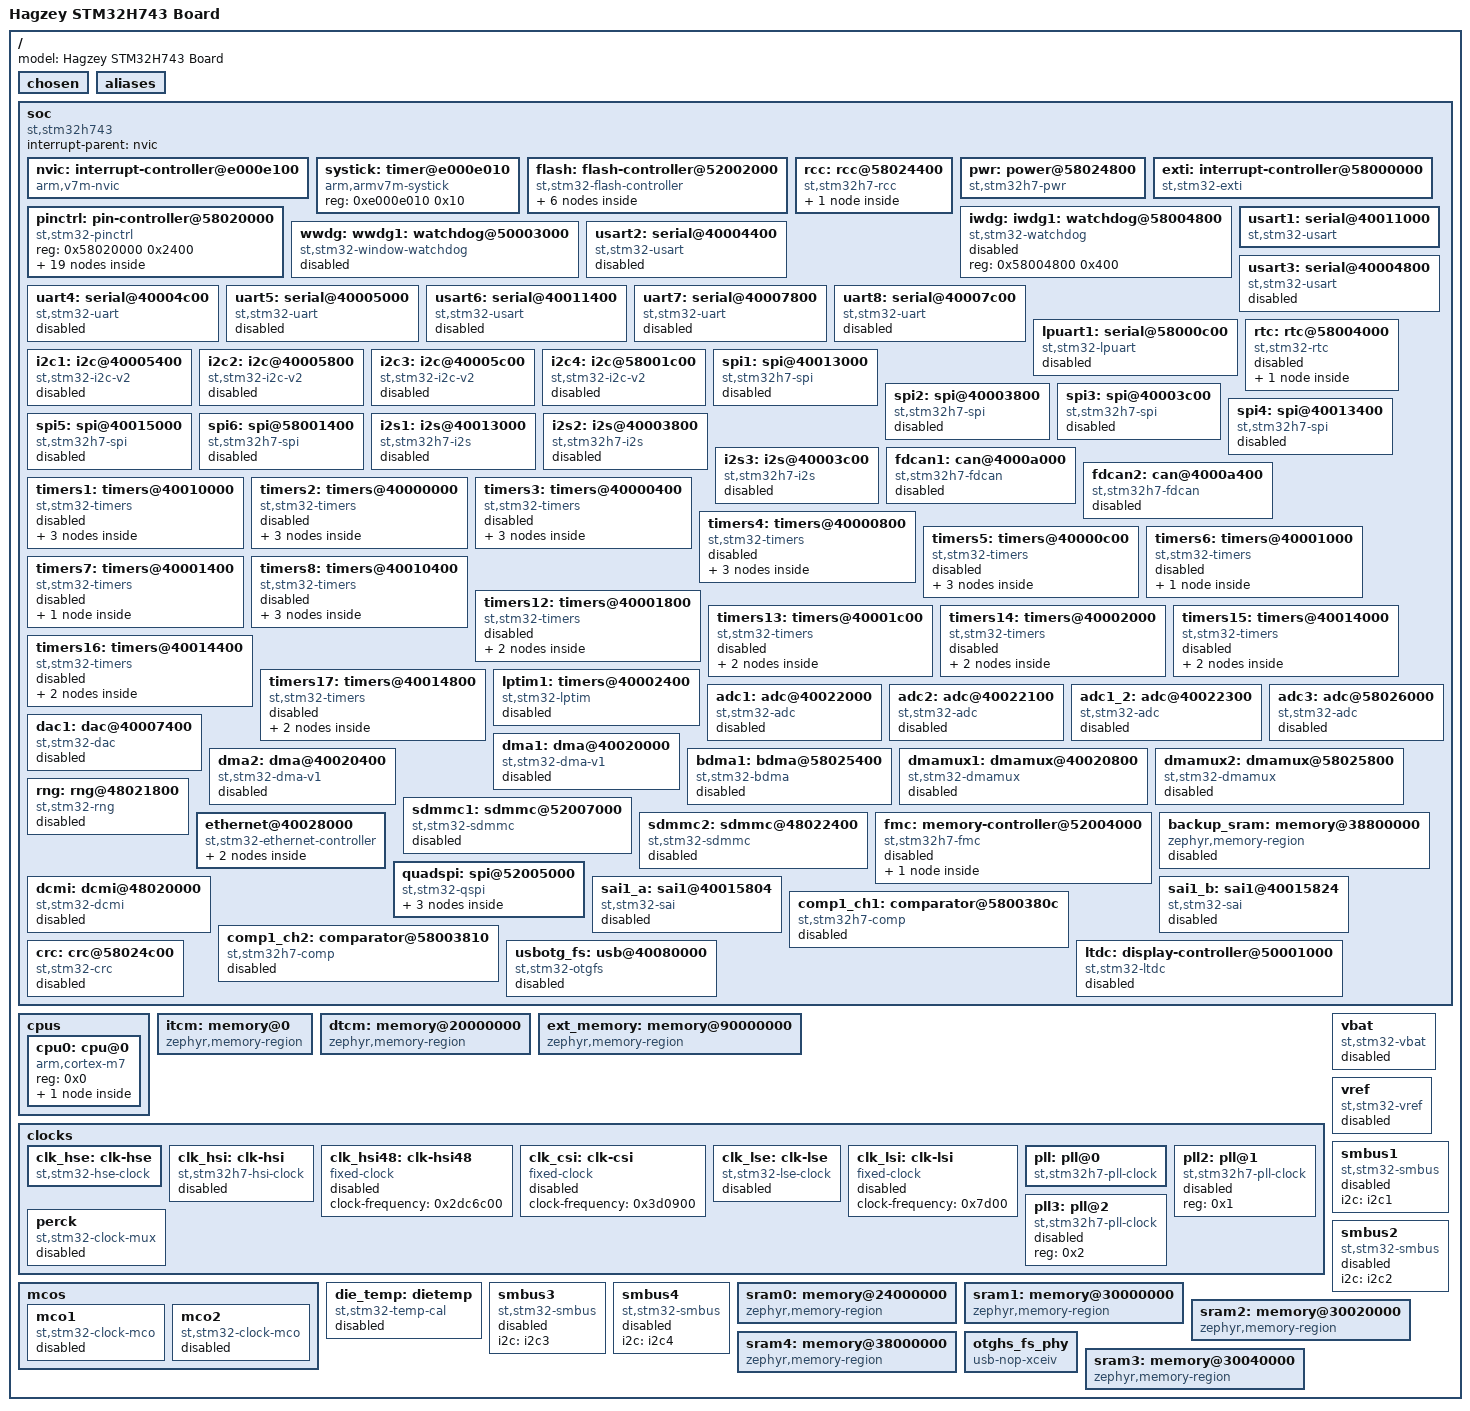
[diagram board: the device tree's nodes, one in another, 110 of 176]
/dts-v1/;

/* node '/' defined in zephyr/dts/common/skeleton.dtsi:9 */
/ {
	#address-cells = < 0x1 >;         /* in zephyr/dts/common/skeleton.dtsi:10 */
	#size-cells = < 0x1 >;            /* in zephyr/dts/common/skeleton.dtsi:11 */
	model = "Hagzey STM32H743 Board"; /* in ../Projects/stm32_system_on_module/fw/som/boards/hagzey/som/som.dts:8 */

	/* node '/chosen' defined in zephyr/dts/common/skeleton.dtsi:13 */
	chosen {
		zephyr,crc = &crc;                /* in zephyr/dts/arm/st/h7/stm32h7.dtsi:29 */
		zephyr,entropy = &rng;            /* in zephyr/dts/arm/st/h7/stm32h7.dtsi:30 */
		zephyr,flash-controller = &flash; /* in zephyr/dts/arm/st/h7/stm32h7.dtsi:31 */
		zephyr,sram = &sram0;             /* in ../Projects/stm32_system_on_module/fw/som/boards/hagzey/som/som.dts:11 */
		zephyr,flash = &flash0;           /* in ../Projects/stm32_system_on_module/fw/som/boards/hagzey/som/som.dts:12 */
		zephyr,console = &usart1;         /* in ../Projects/stm32_system_on_module/fw/som/boards/hagzey/som/som.dts:13 */
		zephyr,shell-uart = &usart1;      /* in ../Projects/stm32_system_on_module/fw/som/boards/hagzey/som/som.dts:14 */
	};

	/* node '/aliases' defined in zephyr/dts/common/skeleton.dtsi:15 */
	aliases {
	};

	/* node '/soc' defined in zephyr/dts/arm/armv7-m.dtsi:6 */
	soc {
		#address-cells = < 0x1 >;     /* in zephyr/dts/arm/armv7-m.dtsi:7 */
		#size-cells = < 0x1 >;        /* in zephyr/dts/arm/armv7-m.dtsi:8 */
		interrupt-parent = < &nvic >; /* in zephyr/dts/arm/armv7-m.dtsi:10 */
		ranges;                       /* in zephyr/dts/arm/armv7-m.dtsi:11 */
		compatible = "st,stm32h743",
		             "st,stm32h7",
		             "simple-bus";    /* in zephyr/dts/arm/st/h7/stm32h743.dtsi:12 */

		/* node '/soc/interrupt-controller@e000e100' defined in zephyr/dts/arm/armv7-m.dtsi:13 */
		nvic: interrupt-controller@e000e100 {
			#address-cells = < 0x1 >;            /* in zephyr/dts/arm/armv7-m.dtsi:14 */
			compatible = "arm,v7m-nvic";         /* in zephyr/dts/arm/armv7-m.dtsi:15 */
			reg = < 0xe000e100 0xc00 >;          /* in zephyr/dts/arm/armv7-m.dtsi:16 */
			interrupt-controller;                /* in zephyr/dts/arm/armv7-m.dtsi:17 */
			#interrupt-cells = < 0x2 >;          /* in zephyr/dts/arm/armv7-m.dtsi:18 */
			arm,num-irq-priority-bits = < 0x4 >; /* in zephyr/dts/arm/st/h7/stm32h7.dtsi:1355 */
			phandle = < 0x1 >;                   /* in zephyr/dts/arm/armv7-m.dtsi:10 */
		};

		/* node '/soc/timer@e000e010' defined in zephyr/dts/arm/armv7-m.dtsi:21 */
		systick: timer@e000e010 {
			compatible = "arm,armv7m-systick"; /* in zephyr/dts/arm/armv7-m.dtsi:22 */
			reg = < 0xe000e010 0x10 >;         /* in zephyr/dts/arm/armv7-m.dtsi:23 */
		};

		/* node '/soc/flash-controller@52002000' defined in zephyr/dts/arm/st/h7/stm32h7.dtsi:162 */
		flash: flash-controller@52002000 {
			compatible = "st,stm32-flash-controller",
			             "st,stm32h7-flash-controller"; /* in zephyr/dts/arm/st/h7/stm32h7.dtsi:163 */
			reg = < 0x52002000 0x400 >;                 /* in zephyr/dts/arm/st/h7/stm32h7.dtsi:164 */
			interrupts = < 0x4 0x0 >;                   /* in zephyr/dts/arm/st/h7/stm32h7.dtsi:165 */
			#address-cells = < 0x1 >;                   /* in zephyr/dts/arm/st/h7/stm32h7.dtsi:167 */
			#size-cells = < 0x1 >;                      /* in zephyr/dts/arm/st/h7/stm32h7.dtsi:168 */

			/* node '/soc/flash-controller@52002000/flash@1ff1e000' defined in zephyr/dts/arm/st/h7/stm32h7.dtsi:174 */
			flash@1ff1e000 {
				compatible = "st,stm32-nvm-otp"; /* in zephyr/dts/arm/st/h7/stm32h7.dtsi:175 */
				reg = < 0x1ff1e000 0x2000 >;     /* in zephyr/dts/arm/st/h7/stm32h7.dtsi:176 */

				/* node '/soc/flash-controller@52002000/flash@1ff1e000/nvmem-layout' defined in zephyr/dts/arm/st/h7/stm32h7.dtsi:178 */
				nvmem-layout {
					compatible = "fixed-layout"; /* in zephyr/dts/arm/st/h7/stm32h7.dtsi:179 */
					#address-cells = < 0x1 >;    /* in zephyr/dts/arm/st/h7/stm32h7.dtsi:180 */
					#size-cells = < 0x1 >;       /* in zephyr/dts/arm/st/h7/stm32h7.dtsi:181 */

					/* node '/soc/flash-controller@52002000/flash@1ff1e000/nvmem-layout/ts-cal1@820' defined in zephyr/dts/arm/st/h7/stm32h7.dtsi:183 */
					ts_cal1_otp: ts-cal1@820 {
						reg = < 0x820 0x2 >;         /* in zephyr/dts/arm/st/h7/stm32h7.dtsi:184 */
						#nvmem-cell-cells = < 0x0 >; /* in zephyr/dts/arm/st/h7/stm32h7.dtsi:185 */
						read-only;                   /* in zephyr/dts/arm/st/h7/stm32h7.dtsi:186 */
						phandle = < 0x12 >;          /* in zephyr/dts/arm/st/h7/stm32h7.dtsi:1297 */
					};

					/* node '/soc/flash-controller@52002000/flash@1ff1e000/nvmem-layout/ts-cal2@840' defined in zephyr/dts/arm/st/h7/stm32h7.dtsi:189 */
					ts_cal2_otp: ts-cal2@840 {
						reg = < 0x840 0x2 >;         /* in zephyr/dts/arm/st/h7/stm32h7.dtsi:190 */
						#nvmem-cell-cells = < 0x0 >; /* in zephyr/dts/arm/st/h7/stm32h7.dtsi:191 */
						read-only;                   /* in zephyr/dts/arm/st/h7/stm32h7.dtsi:192 */
						phandle = < 0x13 >;          /* in zephyr/dts/arm/st/h7/stm32h7.dtsi:1297 */
					};

					/* node '/soc/flash-controller@52002000/flash@1ff1e000/nvmem-layout/vrefint@860' defined in zephyr/dts/arm/st/h7/stm32h7.dtsi:195 */
					vrefint_otp: vrefint@860 {
						reg = < 0x860 0x2 >;         /* in zephyr/dts/arm/st/h7/stm32h7.dtsi:196 */
						#nvmem-cell-cells = < 0x0 >; /* in zephyr/dts/arm/st/h7/stm32h7.dtsi:197 */
						read-only;                   /* in zephyr/dts/arm/st/h7/stm32h7.dtsi:198 */
						phandle = < 0x15 >;          /* in zephyr/dts/arm/st/h7/stm32h7.dtsi:1315 */
					};
				};
			};

			/* node '/soc/flash-controller@52002000/flash@8000000' defined in zephyr/dts/arm/st/h7/stm32h742.dtsi:15 */
			flash0: flash@8000000 {
				compatible = "st,stm32-nv-flash",
				             "soc-nv-flash";      /* in zephyr/dts/arm/st/h7/stm32h742.dtsi:16 */
				write-block-size = < 0x20 >;      /* in zephyr/dts/arm/st/h7/stm32h742.dtsi:17 */
				erase-block-size = < 0x20000 >;   /* in zephyr/dts/arm/st/h7/stm32h742.dtsi:18 */
				max-erase-time = < 0xfa0 >;       /* in zephyr/dts/arm/st/h7/stm32h742.dtsi:20 */
				reg = < 0x8000000 0x200000 >;     /* in zephyr/dts/arm/st/h7/stm32h743Xi.dtsi:13 */
			};
		};

		/* node '/soc/rcc@58024400' defined in zephyr/dts/arm/st/h7/stm32h7.dtsi:204 */
		rcc: rcc@58024400 {
			compatible = "st,stm32h7-rcc";    /* in zephyr/dts/arm/st/h7/stm32h7.dtsi:205 */
			#clock-cells = < 0x2 >;           /* in zephyr/dts/arm/st/h7/stm32h7.dtsi:206 */
			reg = < 0x58024400 0x400 >;       /* in zephyr/dts/arm/st/h7/stm32h7.dtsi:207 */
			clocks = < &pll >;                /* in ../Projects/stm32_system_on_module/fw/som/boards/hagzey/som/som.dts:77 */
			clock-frequency = < 0x1c9c3800 >; /* in ../Projects/stm32_system_on_module/fw/som/boards/hagzey/som/som.dts:78 */
			d1cpre = < 0x1 >;                 /* in ../Projects/stm32_system_on_module/fw/som/boards/hagzey/som/som.dts:79 */
			hpre = < 0x2 >;                   /* in ../Projects/stm32_system_on_module/fw/som/boards/hagzey/som/som.dts:80 */
			d1ppre = < 0x2 >;                 /* in ../Projects/stm32_system_on_module/fw/som/boards/hagzey/som/som.dts:81 */
			d2ppre1 = < 0x2 >;                /* in ../Projects/stm32_system_on_module/fw/som/boards/hagzey/som/som.dts:82 */
			d2ppre2 = < 0x2 >;                /* in ../Projects/stm32_system_on_module/fw/som/boards/hagzey/som/som.dts:83 */
			d3ppre = < 0x2 >;                 /* in ../Projects/stm32_system_on_module/fw/som/boards/hagzey/som/som.dts:84 */
			phandle = < 0x3 >;                /* in zephyr/dts/arm/st/h7/stm32h7.dtsi:230 */

			/* node '/soc/rcc@58024400/reset-controller' defined in zephyr/dts/arm/st/h7/stm32h7.dtsi:209 */
			rctl: reset-controller {
				compatible = "st,stm32-rcc-rctl"; /* in zephyr/dts/arm/st/h7/stm32h7.dtsi:210 */
				#reset-cells = < 0x1 >;           /* in zephyr/dts/arm/st/h7/stm32h7.dtsi:211 */
				phandle = < 0x4 >;                /* in zephyr/dts/arm/st/h7/stm32h7.dtsi:353 */
			};
		};

		/* node '/soc/power@58024800' defined in zephyr/dts/arm/st/h7/stm32h7.dtsi:215 */
		pwr: power@58024800 {
			compatible = "st,stm32h7-pwr"; /* in zephyr/dts/arm/st/h7/stm32h7.dtsi:220 */
			reg = < 0x58024800 0x400 >;    /* in zephyr/dts/arm/st/h7/stm32h7.dtsi:221 */
			power-supply = "ldo";          /* in ../Projects/stm32_system_on_module/fw/som/boards/hagzey/som/som.dts:89 */
		};

		/* node '/soc/interrupt-controller@58000000' defined in zephyr/dts/arm/st/h7/stm32h7.dtsi:224 */
		exti: interrupt-controller@58000000 {
			compatible = "st,stm32-exti";  /* in zephyr/dts/arm/st/h7/stm32h7.dtsi:225 */
			interrupt-controller;          /* in zephyr/dts/arm/st/h7/stm32h7.dtsi:226 */
			#interrupt-cells = < 0x1 >;    /* in zephyr/dts/arm/st/h7/stm32h7.dtsi:227 */
			#address-cells = < 0x0 >;      /* in zephyr/dts/arm/st/h7/stm32h7.dtsi:228 */
			reg = < 0x58000000 0x400 >;    /* in zephyr/dts/arm/st/h7/stm32h7.dtsi:229 */
			clocks = < &rcc 0xf4 0x2 >;    /* in zephyr/dts/arm/st/h7/stm32h7.dtsi:230 */
			num-lines = < 0x60 >;          /* in zephyr/dts/arm/st/h7/stm32h7.dtsi:231 */
			interrupts = < 0x6 0x0 >,
			             < 0x7 0x0 >,
			             < 0x8 0x0 >,
			             < 0x9 0x0 >,
			             < 0xa 0x0 >,
			             < 0x17 0x0 >,
			             < 0x28 0x0 >;     /* in zephyr/dts/arm/st/h7/stm32h7.dtsi:232 */
			interrupt-names = "line0",
			                  "line1",
			                  "line2",
			                  "line3",
			                  "line4",
			                  "line5-9",
			                  "line10-15"; /* in zephyr/dts/arm/st/h7/stm32h7.dtsi:234 */
			line-ranges = < 0x0 0x1 >,
			              < 0x1 0x1 >,
			              < 0x2 0x1 >,
			              < 0x3 0x1 >,
			              < 0x4 0x1 >,
			              < 0x5 0x5 >,
			              < 0xa 0x6 >;     /* in zephyr/dts/arm/st/h7/stm32h7.dtsi:236 */
		};

		/* node '/soc/pin-controller@58020000' defined in zephyr/dts/arm/st/h7/stm32h7.dtsi:240 */
		pinctrl: pin-controller@58020000 {
			compatible = "st,stm32-pinctrl"; /* in zephyr/dts/arm/st/h7/stm32h7.dtsi:241 */
			#address-cells = < 0x1 >;        /* in zephyr/dts/arm/st/h7/stm32h7.dtsi:242 */
			#size-cells = < 0x1 >;           /* in zephyr/dts/arm/st/h7/stm32h7.dtsi:243 */
			reg = < 0x58020000 0x2400 >;     /* in zephyr/dts/arm/st/h7/stm32h7.dtsi:244 */

			/* node '/soc/pin-controller@58020000/gpio@58020000' defined in zephyr/dts/arm/st/h7/stm32h7.dtsi:246 */
			gpioa: gpio@58020000 {
				compatible = "st,stm32-gpio"; /* in zephyr/dts/arm/st/h7/stm32h7.dtsi:247 */
				gpio-controller;              /* in zephyr/dts/arm/st/h7/stm32h7.dtsi:248 */
				#gpio-cells = < 0x2 >;        /* in zephyr/dts/arm/st/h7/stm32h7.dtsi:249 */
				reg = < 0x58020000 0x400 >;   /* in zephyr/dts/arm/st/h7/stm32h7.dtsi:250 */
				clocks = < &rcc 0xe0 0x1 >;   /* in zephyr/dts/arm/st/h7/stm32h7.dtsi:251 */
			};

			/* node '/soc/pin-controller@58020000/gpio@58020400' defined in zephyr/dts/arm/st/h7/stm32h7.dtsi:254 */
			gpiob: gpio@58020400 {
				compatible = "st,stm32-gpio"; /* in zephyr/dts/arm/st/h7/stm32h7.dtsi:255 */
				gpio-controller;              /* in zephyr/dts/arm/st/h7/stm32h7.dtsi:256 */
				#gpio-cells = < 0x2 >;        /* in zephyr/dts/arm/st/h7/stm32h7.dtsi:257 */
				reg = < 0x58020400 0x400 >;   /* in zephyr/dts/arm/st/h7/stm32h7.dtsi:258 */
				clocks = < &rcc 0xe0 0x2 >;   /* in zephyr/dts/arm/st/h7/stm32h7.dtsi:259 */
			};

			/* node '/soc/pin-controller@58020000/gpio@58020800' defined in zephyr/dts/arm/st/h7/stm32h7.dtsi:262 */
			gpioc: gpio@58020800 {
				compatible = "st,stm32-gpio"; /* in zephyr/dts/arm/st/h7/stm32h7.dtsi:263 */
				gpio-controller;              /* in zephyr/dts/arm/st/h7/stm32h7.dtsi:264 */
				#gpio-cells = < 0x2 >;        /* in zephyr/dts/arm/st/h7/stm32h7.dtsi:265 */
				reg = < 0x58020800 0x400 >;   /* in zephyr/dts/arm/st/h7/stm32h7.dtsi:266 */
				clocks = < &rcc 0xe0 0x4 >;   /* in zephyr/dts/arm/st/h7/stm32h7.dtsi:267 */
			};

			/* node '/soc/pin-controller@58020000/gpio@58020c00' defined in zephyr/dts/arm/st/h7/stm32h7.dtsi:270 */
			gpiod: gpio@58020c00 {
				compatible = "st,stm32-gpio"; /* in zephyr/dts/arm/st/h7/stm32h7.dtsi:271 */
				gpio-controller;              /* in zephyr/dts/arm/st/h7/stm32h7.dtsi:272 */
				#gpio-cells = < 0x2 >;        /* in zephyr/dts/arm/st/h7/stm32h7.dtsi:273 */
				reg = < 0x58020c00 0x400 >;   /* in zephyr/dts/arm/st/h7/stm32h7.dtsi:274 */
				clocks = < &rcc 0xe0 0x8 >;   /* in zephyr/dts/arm/st/h7/stm32h7.dtsi:275 */
			};

			/* node '/soc/pin-controller@58020000/gpio@58021000' defined in zephyr/dts/arm/st/h7/stm32h7.dtsi:278 */
			gpioe: gpio@58021000 {
				compatible = "st,stm32-gpio"; /* in zephyr/dts/arm/st/h7/stm32h7.dtsi:279 */
				gpio-controller;              /* in zephyr/dts/arm/st/h7/stm32h7.dtsi:280 */
				#gpio-cells = < 0x2 >;        /* in zephyr/dts/arm/st/h7/stm32h7.dtsi:281 */
				reg = < 0x58021000 0x400 >;   /* in zephyr/dts/arm/st/h7/stm32h7.dtsi:282 */
				clocks = < &rcc 0xe0 0x10 >;  /* in zephyr/dts/arm/st/h7/stm32h7.dtsi:283 */
			};

			/* node '/soc/pin-controller@58020000/gpio@58021400' defined in zephyr/dts/arm/st/h7/stm32h7.dtsi:286 */
			gpiof: gpio@58021400 {
				compatible = "st,stm32-gpio"; /* in zephyr/dts/arm/st/h7/stm32h7.dtsi:287 */
				gpio-controller;              /* in zephyr/dts/arm/st/h7/stm32h7.dtsi:288 */
				#gpio-cells = < 0x2 >;        /* in zephyr/dts/arm/st/h7/stm32h7.dtsi:289 */
				reg = < 0x58021400 0x400 >;   /* in zephyr/dts/arm/st/h7/stm32h7.dtsi:290 */
				clocks = < &rcc 0xe0 0x20 >;  /* in zephyr/dts/arm/st/h7/stm32h7.dtsi:291 */
			};

			/* node '/soc/pin-controller@58020000/gpio@58021800' defined in zephyr/dts/arm/st/h7/stm32h7.dtsi:294 */
			gpiog: gpio@58021800 {
				compatible = "st,stm32-gpio"; /* in zephyr/dts/arm/st/h7/stm32h7.dtsi:295 */
				gpio-controller;              /* in zephyr/dts/arm/st/h7/stm32h7.dtsi:296 */
				#gpio-cells = < 0x2 >;        /* in zephyr/dts/arm/st/h7/stm32h7.dtsi:297 */
				reg = < 0x58021800 0x400 >;   /* in zephyr/dts/arm/st/h7/stm32h7.dtsi:298 */
				clocks = < &rcc 0xe0 0x40 >;  /* in zephyr/dts/arm/st/h7/stm32h7.dtsi:299 */
			};

			/* node '/soc/pin-controller@58020000/gpio@58021c00' defined in zephyr/dts/arm/st/h7/stm32h7.dtsi:302 */
			gpioh: gpio@58021c00 {
				compatible = "st,stm32-gpio"; /* in zephyr/dts/arm/st/h7/stm32h7.dtsi:303 */
				gpio-controller;              /* in zephyr/dts/arm/st/h7/stm32h7.dtsi:304 */
				#gpio-cells = < 0x2 >;        /* in zephyr/dts/arm/st/h7/stm32h7.dtsi:305 */
				reg = < 0x58021c00 0x400 >;   /* in zephyr/dts/arm/st/h7/stm32h7.dtsi:306 */
				clocks = < &rcc 0xe0 0x80 >;  /* in zephyr/dts/arm/st/h7/stm32h7.dtsi:307 */
			};

			/* node '/soc/pin-controller@58020000/gpio@58022000' defined in zephyr/dts/arm/st/h7/stm32h7.dtsi:310 */
			gpioi: gpio@58022000 {
				compatible = "st,stm32-gpio"; /* in zephyr/dts/arm/st/h7/stm32h7.dtsi:311 */
				gpio-controller;              /* in zephyr/dts/arm/st/h7/stm32h7.dtsi:312 */
				#gpio-cells = < 0x2 >;        /* in zephyr/dts/arm/st/h7/stm32h7.dtsi:313 */
				reg = < 0x58022000 0x400 >;   /* in zephyr/dts/arm/st/h7/stm32h7.dtsi:314 */
				clocks = < &rcc 0xe0 0x100 >; /* in zephyr/dts/arm/st/h7/stm32h7.dtsi:315 */
			};

			/* node '/soc/pin-controller@58020000/gpio@58022400' defined in zephyr/dts/arm/st/h7/stm32h7.dtsi:318 */
			gpioj: gpio@58022400 {
				compatible = "st,stm32-gpio"; /* in zephyr/dts/arm/st/h7/stm32h7.dtsi:319 */
				gpio-controller;              /* in zephyr/dts/arm/st/h7/stm32h7.dtsi:320 */
				#gpio-cells = < 0x2 >;        /* in zephyr/dts/arm/st/h7/stm32h7.dtsi:321 */
				reg = < 0x58022400 0x400 >;   /* in zephyr/dts/arm/st/h7/stm32h7.dtsi:322 */
				clocks = < &rcc 0xe0 0x200 >; /* in zephyr/dts/arm/st/h7/stm32h7.dtsi:323 */
			};

			/* node '/soc/pin-controller@58020000/gpio@58022800' defined in zephyr/dts/arm/st/h7/stm32h7.dtsi:326 */
			gpiok: gpio@58022800 {
				compatible = "st,stm32-gpio"; /* in zephyr/dts/arm/st/h7/stm32h7.dtsi:327 */
				gpio-controller;              /* in zephyr/dts/arm/st/h7/stm32h7.dtsi:328 */
				#gpio-cells = < 0x2 >;        /* in zephyr/dts/arm/st/h7/stm32h7.dtsi:329 */
				reg = < 0x58022800 0x400 >;   /* in zephyr/dts/arm/st/h7/stm32h7.dtsi:330 */
				clocks = < &rcc 0xe0 0x400 >; /* in zephyr/dts/arm/st/h7/stm32h7.dtsi:331 */
			};

			/* node '/soc/pin-controller@58020000/quadspi_bk1_ncs_pb10' defined in modules/hal/stm32/dts/st/h7/stm32h743vitx-pinctrl.dtsi:1854 */
			quadspi_bk1_ncs_pb10: quadspi_bk1_ncs_pb10 {
				pinmux = < 0x349 >;            /* in ../Projects/stm32_system_on_module/fw/som/boards/hagzey/som/som.dts:26 */
				slew-rate = "very-high-speed"; /* in ../Projects/stm32_system_on_module/fw/som/boards/hagzey/som/som.dts:27 */
				phandle = < 0xa >;             /* in ../Projects/stm32_system_on_module/fw/som/boards/hagzey/som/som.dts:95 */
			};

			/* node '/soc/pin-controller@58020000/quadspi_bk1_io2_pe2' defined in modules/hal/stm32/dts/st/h7/stm32h743vitx-pinctrl.dtsi:1889 */
			quadspi_bk1_io2_pe2: quadspi_bk1_io2_pe2 {
				pinmux = < 0x849 >;            /* in ../Projects/stm32_system_on_module/fw/som/boards/hagzey/som/som.dts:41 */
				slew-rate = "very-high-speed"; /* in ../Projects/stm32_system_on_module/fw/som/boards/hagzey/som/som.dts:42 */
				phandle = < 0xd >;             /* in ../Projects/stm32_system_on_module/fw/som/boards/hagzey/som/som.dts:95 */
			};

			/* node '/soc/pin-controller@58020000/usart1_rx_pb15' defined in modules/hal/stm32/dts/st/h7/stm32h743vitx-pinctrl.dtsi:3125 */
			usart1_rx_pb15: usart1_rx_pb15 {
				pinmux = < 0x3e4 >; /* in modules/hal/stm32/dts/st/h7/stm32h743vitx-pinctrl.dtsi:3126 */
				phandle = < 0x6 >;  /* in ../Projects/stm32_system_on_module/fw/som/boards/hagzey/som/som.dts:53 */
			};

			/* node '/soc/pin-controller@58020000/usart1_tx_pb14' defined in modules/hal/stm32/dts/st/h7/stm32h743vitx-pinctrl.dtsi:3223 */
			usart1_tx_pb14: usart1_tx_pb14 {
				pinmux = < 0x3c4 >; /* in modules/hal/stm32/dts/st/h7/stm32h743vitx-pinctrl.dtsi:3224 */
				bias-pull-up;       /* in modules/hal/stm32/dts/st/h7/stm32h743vitx-pinctrl.dtsi:3225 */
				phandle = < 0x5 >;  /* in ../Projects/stm32_system_on_module/fw/som/boards/hagzey/som/som.dts:53 */
			};

			/* node '/soc/pin-controller@58020000/quadspi_clk_pf10' defined in ../Projects/stm32_system_on_module/fw/som/boards/hagzey/som/som.dts:20 */
			quadspi_clk_pf10: quadspi_clk_pf10 {
				pinmux = < 0xb49 >;            /* in ../Projects/stm32_system_on_module/fw/som/boards/hagzey/som/som.dts:21 */
				slew-rate = "very-high-speed"; /* in ../Projects/stm32_system_on_module/fw/som/boards/hagzey/som/som.dts:22 */
				phandle = < 0x9 >;             /* in ../Projects/stm32_system_on_module/fw/som/boards/hagzey/som/som.dts:95 */
			};

			/* node '/soc/pin-controller@58020000/quadspi_bk1_io0_pf8' defined in ../Projects/stm32_system_on_module/fw/som/boards/hagzey/som/som.dts:30 */
			quadspi_bk1_io0_pf8: quadspi_bk1_io0_pf8 {
				pinmux = < 0xb0a >;            /* in ../Projects/stm32_system_on_module/fw/som/boards/hagzey/som/som.dts:31 */
				slew-rate = "very-high-speed"; /* in ../Projects/stm32_system_on_module/fw/som/boards/hagzey/som/som.dts:32 */
				phandle = < 0xb >;             /* in ../Projects/stm32_system_on_module/fw/som/boards/hagzey/som/som.dts:95 */
			};

			/* node '/soc/pin-controller@58020000/quadspi_bk1_io1_pf9' defined in ../Projects/stm32_system_on_module/fw/som/boards/hagzey/som/som.dts:35 */
			quadspi_bk1_io1_pf9: quadspi_bk1_io1_pf9 {
				pinmux = < 0xb2a >;            /* in ../Projects/stm32_system_on_module/fw/som/boards/hagzey/som/som.dts:36 */
				slew-rate = "very-high-speed"; /* in ../Projects/stm32_system_on_module/fw/som/boards/hagzey/som/som.dts:37 */
				phandle = < 0xc >;             /* in ../Projects/stm32_system_on_module/fw/som/boards/hagzey/som/som.dts:95 */
			};

			/* node '/soc/pin-controller@58020000/quadspi_bk1_io3_pf6' defined in ../Projects/stm32_system_on_module/fw/som/boards/hagzey/som/som.dts:45 */
			quadspi_bk1_io3_pf6: quadspi_bk1_io3_pf6 {
				pinmux = < 0xac9 >;            /* in ../Projects/stm32_system_on_module/fw/som/boards/hagzey/som/som.dts:46 */
				slew-rate = "very-high-speed"; /* in ../Projects/stm32_system_on_module/fw/som/boards/hagzey/som/som.dts:47 */
				phandle = < 0xe >;             /* in ../Projects/stm32_system_on_module/fw/som/boards/hagzey/som/som.dts:95 */
			};
		};

		/* node '/soc/watchdog@58004800' defined in zephyr/dts/arm/st/h7/stm32h7.dtsi:335 */
		iwdg: iwdg1: watchdog@58004800 {
			compatible = "st,stm32-watchdog"; /* in zephyr/dts/arm/st/h7/stm32h7.dtsi:336 */
			reg = < 0x58004800 0x400 >;       /* in zephyr/dts/arm/st/h7/stm32h7.dtsi:337 */
			status = "disabled";              /* in zephyr/dts/arm/st/h7/stm32h7.dtsi:338 */
		};

		/* node '/soc/watchdog@50003000' defined in zephyr/dts/arm/st/h7/stm32h7.dtsi:341 */
		wwdg: wwdg1: watchdog@50003000 {
			compatible = "st,stm32-window-watchdog"; /* in zephyr/dts/arm/st/h7/stm32h7.dtsi:342 */
			reg = < 0x50003000 0x1000 >;             /* in zephyr/dts/arm/st/h7/stm32h7.dtsi:343 */
			clocks = < &rcc 0xe4 0x40 >;             /* in zephyr/dts/arm/st/h7/stm32h7.dtsi:344 */
			interrupts = < 0x0 0x7 >;                /* in zephyr/dts/arm/st/h7/stm32h7.dtsi:345 */
			status = "disabled";                     /* in zephyr/dts/arm/st/h7/stm32h7.dtsi:346 */
		};

		/* node '/soc/serial@40011000' defined in zephyr/dts/arm/st/h7/stm32h7.dtsi:349 */
		usart1: serial@40011000 {
			compatible = "st,stm32-usart",
			             "st,stm32-uart";                    /* in zephyr/dts/arm/st/h7/stm32h7.dtsi:350 */
			reg = < 0x40011000 0x400 >;                      /* in zephyr/dts/arm/st/h7/stm32h7.dtsi:351 */
			clocks = < &rcc 0xf0 0x10 >;                     /* in zephyr/dts/arm/st/h7/stm32h7.dtsi:352 */
			resets = < &rctl 0x1304 >;                       /* in zephyr/dts/arm/st/h7/stm32h7.dtsi:353 */
			interrupts = < 0x25 0x0 >;                       /* in zephyr/dts/arm/st/h7/stm32h7.dtsi:354 */
			pinctrl-0 = < &usart1_tx_pb14 &usart1_rx_pb15 >; /* in ../Projects/stm32_system_on_module/fw/som/boards/hagzey/som/som.dts:53 */
			pinctrl-names = "default";                       /* in ../Projects/stm32_system_on_module/fw/som/boards/hagzey/som/som.dts:54 */
			current-speed = < 0xe100 >;                      /* in ../Projects/stm32_system_on_module/fw/som/boards/hagzey/som/som.dts:55 */
			status = "okay";                                 /* in ../Projects/stm32_system_on_module/fw/som/boards/hagzey/som/som.dts:56 */
		};

		/* node '/soc/serial@40004400' defined in zephyr/dts/arm/st/h7/stm32h7.dtsi:358 */
		usart2: serial@40004400 {
			compatible = "st,stm32-usart",
			             "st,stm32-uart";   /* in zephyr/dts/arm/st/h7/stm32h7.dtsi:359 */
			reg = < 0x40004400 0x400 >;     /* in zephyr/dts/arm/st/h7/stm32h7.dtsi:360 */
			clocks = < &rcc 0xe8 0x20000 >; /* in zephyr/dts/arm/st/h7/stm32h7.dtsi:361 */
			resets = < &rctl 0x1211 >;      /* in zephyr/dts/arm/st/h7/stm32h7.dtsi:362 */
			interrupts = < 0x26 0x0 >;      /* in zephyr/dts/arm/st/h7/stm32h7.dtsi:363 */
			status = "disabled";            /* in zephyr/dts/arm/st/h7/stm32h7.dtsi:364 */
		};

		/* node '/soc/serial@40004800' defined in zephyr/dts/arm/st/h7/stm32h7.dtsi:367 */
		usart3: serial@40004800 {
			compatible = "st,stm32-usart",
			             "st,stm32-uart";   /* in zephyr/dts/arm/st/h7/stm32h7.dtsi:368 */
			reg = < 0x40004800 0x400 >;     /* in zephyr/dts/arm/st/h7/stm32h7.dtsi:369 */
			clocks = < &rcc 0xe8 0x40000 >; /* in zephyr/dts/arm/st/h7/stm32h7.dtsi:370 */
			resets = < &rctl 0x1212 >;      /* in zephyr/dts/arm/st/h7/stm32h7.dtsi:371 */
			interrupts = < 0x27 0x0 >;      /* in zephyr/dts/arm/st/h7/stm32h7.dtsi:372 */
			status = "disabled";            /* in zephyr/dts/arm/st/h7/stm32h7.dtsi:373 */
		};

		/* node '/soc/serial@40004c00' defined in zephyr/dts/arm/st/h7/stm32h7.dtsi:376 */
		uart4: serial@40004c00 {
			compatible = "st,stm32-uart";   /* in zephyr/dts/arm/st/h7/stm32h7.dtsi:377 */
			reg = < 0x40004c00 0x400 >;     /* in zephyr/dts/arm/st/h7/stm32h7.dtsi:378 */
			clocks = < &rcc 0xe8 0x80000 >; /* in zephyr/dts/arm/st/h7/stm32h7.dtsi:379 */
			resets = < &rctl 0x1213 >;      /* in zephyr/dts/arm/st/h7/stm32h7.dtsi:380 */
			interrupts = < 0x34 0x0 >;      /* in zephyr/dts/arm/st/h7/stm32h7.dtsi:381 */
			status = "disabled";            /* in zephyr/dts/arm/st/h7/stm32h7.dtsi:382 */
		};

		/* node '/soc/serial@40005000' defined in zephyr/dts/arm/st/h7/stm32h7.dtsi:385 */
		uart5: serial@40005000 {
			compatible = "st,stm32-uart";    /* in zephyr/dts/arm/st/h7/stm32h7.dtsi:386 */
			reg = < 0x40005000 0x400 >;      /* in zephyr/dts/arm/st/h7/stm32h7.dtsi:387 */
			clocks = < &rcc 0xe8 0x100000 >; /* in zephyr/dts/arm/st/h7/stm32h7.dtsi:388 */
			resets = < &rctl 0x1214 >;       /* in zephyr/dts/arm/st/h7/stm32h7.dtsi:389 */
			interrupts = < 0x35 0x0 >;       /* in zephyr/dts/arm/st/h7/stm32h7.dtsi:390 */
			status = "disabled";             /* in zephyr/dts/arm/st/h7/stm32h7.dtsi:391 */
		};

		/* node '/soc/serial@40011400' defined in zephyr/dts/arm/st/h7/stm32h7.dtsi:394 */
		usart6: serial@40011400 {
			compatible = "st,stm32-usart",
			             "st,stm32-uart";  /* in zephyr/dts/arm/st/h7/stm32h7.dtsi:395 */
			reg = < 0x40011400 0x400 >;    /* in zephyr/dts/arm/st/h7/stm32h7.dtsi:396 */
			clocks = < &rcc 0xf0 0x20 >;   /* in zephyr/dts/arm/st/h7/stm32h7.dtsi:397 */
			resets = < &rctl 0x1305 >;     /* in zephyr/dts/arm/st/h7/stm32h7.dtsi:398 */
			interrupts = < 0x47 0x0 >;     /* in zephyr/dts/arm/st/h7/stm32h7.dtsi:399 */
			status = "disabled";           /* in zephyr/dts/arm/st/h7/stm32h7.dtsi:400 */
		};

		/* node '/soc/serial@40007800' defined in zephyr/dts/arm/st/h7/stm32h7.dtsi:403 */
		uart7: serial@40007800 {
			compatible = "st,stm32-uart";      /* in zephyr/dts/arm/st/h7/stm32h7.dtsi:404 */
			reg = < 0x40007800 0x400 >;        /* in zephyr/dts/arm/st/h7/stm32h7.dtsi:405 */
			clocks = < &rcc 0xe8 0x40000000 >; /* in zephyr/dts/arm/st/h7/stm32h7.dtsi:406 */
			resets = < &rctl 0x121e >;         /* in zephyr/dts/arm/st/h7/stm32h7.dtsi:407 */
			interrupts = < 0x52 0x0 >;         /* in zephyr/dts/arm/st/h7/stm32h7.dtsi:408 */
			status = "disabled";               /* in zephyr/dts/arm/st/h7/stm32h7.dtsi:409 */
		};

		/* node '/soc/serial@40007c00' defined in zephyr/dts/arm/st/h7/stm32h7.dtsi:412 */
		uart8: serial@40007c00 {
			compatible = "st,stm32-uart";      /* in zephyr/dts/arm/st/h7/stm32h7.dtsi:413 */
			reg = < 0x40007c00 0x400 >;        /* in zephyr/dts/arm/st/h7/stm32h7.dtsi:414 */
			clocks = < &rcc 0xe8 0x80000000 >; /* in zephyr/dts/arm/st/h7/stm32h7.dtsi:415 */
			resets = < &rctl 0x121f >;         /* in zephyr/dts/arm/st/h7/stm32h7.dtsi:416 */
			interrupts = < 0x53 0x0 >;         /* in zephyr/dts/arm/st/h7/stm32h7.dtsi:417 */
			status = "disabled";               /* in zephyr/dts/arm/st/h7/stm32h7.dtsi:418 */
		};

		/* node '/soc/serial@58000c00' defined in zephyr/dts/arm/st/h7/stm32h7.dtsi:421 */
		lpuart1: serial@58000c00 {
			compatible = "st,stm32-lpuart",
			             "st,stm32-uart";   /* in zephyr/dts/arm/st/h7/stm32h7.dtsi:422 */
			reg = < 0x58000c00 0x400 >;     /* in zephyr/dts/arm/st/h7/stm32h7.dtsi:423 */
			clocks = < &rcc 0xf4 0x8 >;     /* in zephyr/dts/arm/st/h7/stm32h7.dtsi:424 */
			resets = < &rctl 0x1383 >;      /* in zephyr/dts/arm/st/h7/stm32h7.dtsi:425 */
			interrupts = < 0x8e 0x0 >;      /* in zephyr/dts/arm/st/h7/stm32h7.dtsi:426 */
			status = "disabled";            /* in zephyr/dts/arm/st/h7/stm32h7.dtsi:427 */
		};

		/* node '/soc/rtc@58004000' defined in zephyr/dts/arm/st/h7/stm32h7.dtsi:430 */
		rtc: rtc@58004000 {
			compatible = "st,stm32-rtc";    /* in zephyr/dts/arm/st/h7/stm32h7.dtsi:431 */
			reg = < 0x58004000 0x400 >;     /* in zephyr/dts/arm/st/h7/stm32h7.dtsi:432 */
			interrupts = < 0x29 0x0 >;      /* in zephyr/dts/arm/st/h7/stm32h7.dtsi:433 */
			clocks = < &rcc 0xf4 0x10000 >; /* in zephyr/dts/arm/st/h7/stm32h7.dtsi:434 */
			prescaler = < 0x8000 >;         /* in zephyr/dts/arm/st/h7/stm32h7.dtsi:435 */
			alarms-count = < 0x2 >;         /* in zephyr/dts/arm/st/h7/stm32h7.dtsi:436 */
			alrm-exti-line = < 0x11 >;      /* in zephyr/dts/arm/st/h7/stm32h7.dtsi:437 */
			status = "disabled";            /* in zephyr/dts/arm/st/h7/stm32h7.dtsi:438 */

			/* node '/soc/rtc@58004000/backup_regs' defined in zephyr/dts/arm/st/h7/stm32h742.dtsi:57 */
			bbram: backup_regs {
				compatible = "st,stm32-bbram"; /* in zephyr/dts/arm/st/h7/stm32h742.dtsi:58 */
				st,backup-regs = < 0x20 >;     /* in zephyr/dts/arm/st/h7/stm32h742.dtsi:59 */
				status = "disabled";           /* in zephyr/dts/arm/st/h7/stm32h742.dtsi:60 */
			};
		};

		/* node '/soc/i2c@40005400' defined in zephyr/dts/arm/st/h7/stm32h7.dtsi:441 */
		i2c1: i2c@40005400 {
			compatible = "st,stm32-i2c-v2";  /* in zephyr/dts/arm/st/h7/stm32h7.dtsi:442 */
			clock-frequency = < 0x186a0 >;   /* in zephyr/dts/arm/st/h7/stm32h7.dtsi:443 */
			#address-cells = < 0x1 >;        /* in zephyr/dts/arm/st/h7/stm32h7.dtsi:444 */
			#size-cells = < 0x0 >;           /* in zephyr/dts/arm/st/h7/stm32h7.dtsi:445 */
			reg = < 0x40005400 0x400 >;      /* in zephyr/dts/arm/st/h7/stm32h7.dtsi:446 */
			clocks = < &rcc 0xe8 0x200000 >; /* in zephyr/dts/arm/st/h7/stm32h7.dtsi:447 */
			interrupts = < 0x1f 0x0 >,
			             < 0x20 0x0 >;       /* in zephyr/dts/arm/st/h7/stm32h7.dtsi:448 */
			interrupt-names = "event",
			                  "error";       /* in zephyr/dts/arm/st/h7/stm32h7.dtsi:449 */
			status = "disabled";             /* in zephyr/dts/arm/st/h7/stm32h7.dtsi:450 */
			phandle = < 0x16 >;              /* in zephyr/dts/arm/st/h7/stm32h7.dtsi:1325 */
		};

		/* node '/soc/i2c@40005800' defined in zephyr/dts/arm/st/h7/stm32h7.dtsi:453 */
		i2c2: i2c@40005800 {
			compatible = "st,stm32-i2c-v2";  /* in zephyr/dts/arm/st/h7/stm32h7.dtsi:454 */
			clock-frequency = < 0x186a0 >;   /* in zephyr/dts/arm/st/h7/stm32h7.dtsi:455 */
			#address-cells = < 0x1 >;        /* in zephyr/dts/arm/st/h7/stm32h7.dtsi:456 */
			#size-cells = < 0x0 >;           /* in zephyr/dts/arm/st/h7/stm32h7.dtsi:457 */
			reg = < 0x40005800 0x400 >;      /* in zephyr/dts/arm/st/h7/stm32h7.dtsi:458 */
			clocks = < &rcc 0xe8 0x400000 >; /* in zephyr/dts/arm/st/h7/stm32h7.dtsi:459 */
			interrupts = < 0x21 0x0 >,
			             < 0x22 0x0 >;       /* in zephyr/dts/arm/st/h7/stm32h7.dtsi:460 */
			interrupt-names = "event",
			                  "error";       /* in zephyr/dts/arm/st/h7/stm32h7.dtsi:461 */
			status = "disabled";             /* in zephyr/dts/arm/st/h7/stm32h7.dtsi:462 */
			phandle = < 0x17 >;              /* in zephyr/dts/arm/st/h7/stm32h7.dtsi:1333 */
		};

		/* node '/soc/i2c@40005c00' defined in zephyr/dts/arm/st/h7/stm32h7.dtsi:465 */
		i2c3: i2c@40005c00 {
			compatible = "st,stm32-i2c-v2";  /* in zephyr/dts/arm/st/h7/stm32h7.dtsi:466 */
			clock-frequency = < 0x186a0 >;   /* in zephyr/dts/arm/st/h7/stm32h7.dtsi:467 */
			#address-cells = < 0x1 >;        /* in zephyr/dts/arm/st/h7/stm32h7.dtsi:468 */
			#size-cells = < 0x0 >;           /* in zephyr/dts/arm/st/h7/stm32h7.dtsi:469 */
			reg = < 0x40005c00 0x400 >;      /* in zephyr/dts/arm/st/h7/stm32h7.dtsi:470 */
			clocks = < &rcc 0xe8 0x800000 >; /* in zephyr/dts/arm/st/h7/stm32h7.dtsi:471 */
			interrupts = < 0x48 0x0 >,
			             < 0x49 0x0 >;       /* in zephyr/dts/arm/st/h7/stm32h7.dtsi:472 */
			interrupt-names = "event",
			                  "error";       /* in zephyr/dts/arm/st/h7/stm32h7.dtsi:473 */
			status = "disabled";             /* in zephyr/dts/arm/st/h7/stm32h7.dtsi:474 */
			phandle = < 0x18 >;              /* in zephyr/dts/arm/st/h7/stm32h7.dtsi:1341 */
		};

		/* node '/soc/i2c@58001c00' defined in zephyr/dts/arm/st/h7/stm32h7.dtsi:477 */
		i2c4: i2c@58001c00 {
			compatible = "st,stm32-i2c-v2"; /* in zephyr/dts/arm/st/h7/stm32h7.dtsi:478 */
			clock-frequency = < 0x186a0 >;  /* in zephyr/dts/arm/st/h7/stm32h7.dtsi:479 */
			#address-cells = < 0x1 >;       /* in zephyr/dts/arm/st/h7/stm32h7.dtsi:480 */
			#size-cells = < 0x0 >;          /* in zephyr/dts/arm/st/h7/stm32h7.dtsi:481 */
			reg = < 0x58001c00 0x400 >;     /* in zephyr/dts/arm/st/h7/stm32h7.dtsi:482 */
			clocks = < &rcc 0xf4 0x80 >;    /* in zephyr/dts/arm/st/h7/stm32h7.dtsi:483 */
			interrupts = < 0x5f 0x0 >,
			             < 0x60 0x0 >;      /* in zephyr/dts/arm/st/h7/stm32h7.dtsi:484 */
			interrupt-names = "event",
			                  "error";      /* in zephyr/dts/arm/st/h7/stm32h7.dtsi:485 */
			status = "disabled";            /* in zephyr/dts/arm/st/h7/stm32h7.dtsi:486 */
			phandle = < 0x19 >;             /* in zephyr/dts/arm/st/h7/stm32h7.dtsi:1349 */
		};

		/* node '/soc/spi@40013000' defined in zephyr/dts/arm/st/h7/stm32h7.dtsi:489 */
		spi1: spi@40013000 {
			compatible = "st,stm32h7-spi",
			             "st,stm32-spi-fifo",
			             "st,stm32-spi";            /* in zephyr/dts/arm/st/h7/stm32h7.dtsi:490 */
			#address-cells = < 0x1 >;               /* in zephyr/dts/arm/st/h7/stm32h7.dtsi:491 */
			#size-cells = < 0x0 >;                  /* in zephyr/dts/arm/st/h7/stm32h7.dtsi:492 */
			reg = < 0x40013000 0x400 >;             /* in zephyr/dts/arm/st/h7/stm32h7.dtsi:493 */
			clocks = < &rcc 0xf0 0x1000 >,
			         < &rcc 0x9 0x4c0050 >;         /* in zephyr/dts/arm/st/h7/stm32h7.dtsi:494 */
			interrupts = < 0x23 0x0 >;              /* in zephyr/dts/arm/st/h7/stm32h7.dtsi:496 */
			st,spi-data-width = "full-4-to-32-bit"; /* in zephyr/dts/arm/st/h7/stm32h7.dtsi:497 */
			fifo-size = < 0x10 >;                   /* in zephyr/dts/arm/st/h7/stm32h7.dtsi:498 */
			fifo-max-transfer-size = < 0xffff >;    /* in zephyr/dts/arm/st/h7/stm32h7.dtsi:499 */
			status = "disabled";                    /* in zephyr/dts/arm/st/h7/stm32h7.dtsi:500 */
		};

		/* node '/soc/spi@40003800' defined in zephyr/dts/arm/st/h7/stm32h7.dtsi:503 */
		spi2: spi@40003800 {
			compatible = "st,stm32h7-spi",
			             "st,stm32-spi-fifo",
			             "st,stm32-spi";            /* in zephyr/dts/arm/st/h7/stm32h7.dtsi:504 */
			#address-cells = < 0x1 >;               /* in zephyr/dts/arm/st/h7/stm32h7.dtsi:505 */
			#size-cells = < 0x0 >;                  /* in zephyr/dts/arm/st/h7/stm32h7.dtsi:506 */
			reg = < 0x40003800 0x400 >;             /* in zephyr/dts/arm/st/h7/stm32h7.dtsi:507 */
			clocks = < &rcc 0xe8 0x4000 >,
			         < &rcc 0x9 0x4c0050 >;         /* in zephyr/dts/arm/st/h7/stm32h7.dtsi:508 */
			interrupts = < 0x24 0x0 >;              /* in zephyr/dts/arm/st/h7/stm32h7.dtsi:510 */
			st,spi-data-width = "full-4-to-32-bit"; /* in zephyr/dts/arm/st/h7/stm32h7.dtsi:511 */
			fifo-size = < 0x10 >;                   /* in zephyr/dts/arm/st/h7/stm32h7.dtsi:512 */
			fifo-max-transfer-size = < 0xffff >;    /* in zephyr/dts/arm/st/h7/stm32h7.dtsi:513 */
			status = "disabled";                    /* in zephyr/dts/arm/st/h7/stm32h7.dtsi:514 */
		};

		/* node '/soc/spi@40003c00' defined in zephyr/dts/arm/st/h7/stm32h7.dtsi:517 */
		spi3: spi@40003c00 {
			compatible = "st,stm32h7-spi",
			             "st,stm32-spi-fifo",
			             "st,stm32-spi";            /* in zephyr/dts/arm/st/h7/stm32h7.dtsi:518 */
			#address-cells = < 0x1 >;               /* in zephyr/dts/arm/st/h7/stm32h7.dtsi:519 */
			#size-cells = < 0x0 >;                  /* in zephyr/dts/arm/st/h7/stm32h7.dtsi:520 */
			reg = < 0x40003c00 0x400 >;             /* in zephyr/dts/arm/st/h7/stm32h7.dtsi:521 */
			clocks = < &rcc 0xe8 0x8000 >,
			         < &rcc 0x9 0x4c0050 >;         /* in zephyr/dts/arm/st/h7/stm32h7.dtsi:522 */
			interrupts = < 0x33 0x0 >;              /* in zephyr/dts/arm/st/h7/stm32h7.dtsi:524 */
			st,spi-data-width = "full-4-to-32-bit"; /* in zephyr/dts/arm/st/h7/stm32h7.dtsi:525 */
			fifo-size = < 0x10 >;                   /* in zephyr/dts/arm/st/h7/stm32h7.dtsi:526 */
			fifo-max-transfer-size = < 0xffff >;    /* in zephyr/dts/arm/st/h7/stm32h7.dtsi:527 */
			status = "disabled";                    /* in zephyr/dts/arm/st/h7/stm32h7.dtsi:528 */
		};

		/* node '/soc/spi@40013400' defined in zephyr/dts/arm/st/h7/stm32h7.dtsi:531 */
		spi4: spi@40013400 {
			compatible = "st,stm32h7-spi",
			             "st,stm32-spi-fifo",
			             "st,stm32-spi";            /* in zephyr/dts/arm/st/h7/stm32h7.dtsi:532 */
			#address-cells = < 0x1 >;               /* in zephyr/dts/arm/st/h7/stm32h7.dtsi:533 */
			#size-cells = < 0x0 >;                  /* in zephyr/dts/arm/st/h7/stm32h7.dtsi:534 */
			reg = < 0x40013400 0x400 >;             /* in zephyr/dts/arm/st/h7/stm32h7.dtsi:535 */
			clocks = < &rcc 0xf0 0x2000 >;          /* in zephyr/dts/arm/st/h7/stm32h7.dtsi:536 */
			interrupts = < 0x54 0x0 >;              /* in zephyr/dts/arm/st/h7/stm32h7.dtsi:537 */
			st,spi-data-width = "full-4-to-16-bit"; /* in zephyr/dts/arm/st/h7/stm32h7.dtsi:538 */
			status = "disabled";                    /* in zephyr/dts/arm/st/h7/stm32h7.dtsi:539 */
			fifo-size = < 0x8 >;                    /* in zephyr/dts/arm/st/h7/stm32h7.dtsi:540 */
			fifo-max-transfer-size = < 0xffff >;    /* in zephyr/dts/arm/st/h7/stm32h7.dtsi:541 */
		};

		/* node '/soc/spi@40015000' defined in zephyr/dts/arm/st/h7/stm32h7.dtsi:544 */
		spi5: spi@40015000 {
			compatible = "st,stm32h7-spi",
			             "st,stm32-spi-fifo",
			             "st,stm32-spi";            /* in zephyr/dts/arm/st/h7/stm32h7.dtsi:545 */
			#address-cells = < 0x1 >;               /* in zephyr/dts/arm/st/h7/stm32h7.dtsi:546 */
			#size-cells = < 0x0 >;                  /* in zephyr/dts/arm/st/h7/stm32h7.dtsi:547 */
			reg = < 0x40015000 0x400 >;             /* in zephyr/dts/arm/st/h7/stm32h7.dtsi:548 */
			clocks = < &rcc 0xf0 0x100000 >;        /* in zephyr/dts/arm/st/h7/stm32h7.dtsi:549 */
			interrupts = < 0x55 0x0 >;              /* in zephyr/dts/arm/st/h7/stm32h7.dtsi:550 */
			st,spi-data-width = "full-4-to-16-bit"; /* in zephyr/dts/arm/st/h7/stm32h7.dtsi:551 */
			fifo-size = < 0x8 >;                    /* in zephyr/dts/arm/st/h7/stm32h7.dtsi:552 */
			fifo-max-transfer-size = < 0xffff >;    /* in zephyr/dts/arm/st/h7/stm32h7.dtsi:553 */
			status = "disabled";                    /* in zephyr/dts/arm/st/h7/stm32h7.dtsi:554 */
		};

		/* node '/soc/spi@58001400' defined in zephyr/dts/arm/st/h7/stm32h7.dtsi:557 */
		spi6: spi@58001400 {
			compatible = "st,stm32h7-spi",
			             "st,stm32-spi-fifo",
			             "st,stm32-spi";            /* in zephyr/dts/arm/st/h7/stm32h7.dtsi:558 */
			#address-cells = < 0x1 >;               /* in zephyr/dts/arm/st/h7/stm32h7.dtsi:559 */
			#size-cells = < 0x0 >;                  /* in zephyr/dts/arm/st/h7/stm32h7.dtsi:560 */
			reg = < 0x58001400 0x400 >;             /* in zephyr/dts/arm/st/h7/stm32h7.dtsi:561 */
			clocks = < &rcc 0xf4 0x20 >;            /* in zephyr/dts/arm/st/h7/stm32h7.dtsi:562 */
			interrupts = < 0x56 0x0 >;              /* in zephyr/dts/arm/st/h7/stm32h7.dtsi:563 */
			st,spi-data-width = "full-4-to-16-bit"; /* in zephyr/dts/arm/st/h7/stm32h7.dtsi:564 */
			fifo-size = < 0x8 >;                    /* in zephyr/dts/arm/st/h7/stm32h7.dtsi:565 */
			fifo-max-transfer-size = < 0xffff >;    /* in zephyr/dts/arm/st/h7/stm32h7.dtsi:566 */
			status = "disabled";                    /* in zephyr/dts/arm/st/h7/stm32h7.dtsi:567 */
		};

		/* node '/soc/i2s@40013000' defined in zephyr/dts/arm/st/h7/stm32h7.dtsi:570 */
		i2s1: i2s@40013000 {
			compatible = "st,stm32h7-i2s",
			             "st,stm32-i2s";          /* in zephyr/dts/arm/st/h7/stm32h7.dtsi:571 */
			#address-cells = < 0x1 >;             /* in zephyr/dts/arm/st/h7/stm32h7.dtsi:572 */
			#size-cells = < 0x0 >;                /* in zephyr/dts/arm/st/h7/stm32h7.dtsi:573 */
			reg = < 0x40013000 0x400 >;           /* in zephyr/dts/arm/st/h7/stm32h7.dtsi:574 */
			clocks = < &rcc 0xf0 0x1000 >,
			         < &rcc 0x9 0x4c0050 >;       /* in zephyr/dts/arm/st/h7/stm32h7.dtsi:575 */
			dmas = < &dmamux1 0x0 0x26 0x20440 >,
			       < &dmamux1 0x1 0x25 0x20480 >; /* in zephyr/dts/arm/st/h7/stm32h7.dtsi:577 */
			dma-names = "tx",
			            "rx";                     /* in zephyr/dts/arm/st/h7/stm32h7.dtsi:579 */
			interrupts = < 0x23 0x3 >;            /* in zephyr/dts/arm/st/h7/stm32h7.dtsi:580 */
			status = "disabled";                  /* in zephyr/dts/arm/st/h7/stm32h7.dtsi:581 */
		};

		/* node '/soc/i2s@40003800' defined in zephyr/dts/arm/st/h7/stm32h7.dtsi:584 */
		i2s2: i2s@40003800 {
			compatible = "st,stm32h7-i2s",
			             "st,stm32-i2s";          /* in zephyr/dts/arm/st/h7/stm32h7.dtsi:585 */
			#address-cells = < 0x1 >;             /* in zephyr/dts/arm/st/h7/stm32h7.dtsi:586 */
			#size-cells = < 0x0 >;                /* in zephyr/dts/arm/st/h7/stm32h7.dtsi:587 */
			reg = < 0x40003800 0x400 >;           /* in zephyr/dts/arm/st/h7/stm32h7.dtsi:588 */
			clocks = < &rcc 0xe8 0x4000 >,
			         < &rcc 0x9 0x4c0050 >;       /* in zephyr/dts/arm/st/h7/stm32h7.dtsi:589 */
			dmas = < &dmamux1 0x0 0x28 0x20440 >,
			       < &dmamux1 0x1 0x27 0x20480 >; /* in zephyr/dts/arm/st/h7/stm32h7.dtsi:591 */
			dma-names = "tx",
			            "rx";                     /* in zephyr/dts/arm/st/h7/stm32h7.dtsi:593 */
			interrupts = < 0x24 0x0 >;            /* in zephyr/dts/arm/st/h7/stm32h7.dtsi:594 */
			status = "disabled";                  /* in zephyr/dts/arm/st/h7/stm32h7.dtsi:595 */
		};

		/* node '/soc/i2s@40003c00' defined in zephyr/dts/arm/st/h7/stm32h7.dtsi:598 */
		i2s3: i2s@40003c00 {
			compatible = "st,stm32h7-i2s",
			             "st,stm32-i2s";          /* in zephyr/dts/arm/st/h7/stm32h7.dtsi:599 */
			#address-cells = < 0x1 >;             /* in zephyr/dts/arm/st/h7/stm32h7.dtsi:600 */
			#size-cells = < 0x0 >;                /* in zephyr/dts/arm/st/h7/stm32h7.dtsi:601 */
			reg = < 0x40003c00 0x400 >;           /* in zephyr/dts/arm/st/h7/stm32h7.dtsi:602 */
			clocks = < &rcc 0xe8 0x8000 >,
			         < &rcc 0x9 0x4c0050 >;       /* in zephyr/dts/arm/st/h7/stm32h7.dtsi:603 */
			dmas = < &dmamux1 0x0 0x3e 0x20440 >,
			       < &dmamux1 0x1 0x3d 0x20480 >; /* in zephyr/dts/arm/st/h7/stm32h7.dtsi:605 */
			dma-names = "tx",
			            "rx";                     /* in zephyr/dts/arm/st/h7/stm32h7.dtsi:607 */
			interrupts = < 0x33 0x0 >;            /* in zephyr/dts/arm/st/h7/stm32h7.dtsi:608 */
			status = "disabled";                  /* in zephyr/dts/arm/st/h7/stm32h7.dtsi:609 */
		};

		/* node '/soc/can@4000a000' defined in zephyr/dts/arm/st/h7/stm32h7.dtsi:612 */
		fdcan1: can@4000a000 {
			compatible = "st,stm32h7-fdcan";                       /* in zephyr/dts/arm/st/h7/stm32h7.dtsi:613 */
			reg = < 0x4000a000 0x400 >,
			      < 0x4000ac00 0x350 >;                            /* in zephyr/dts/arm/st/h7/stm32h7.dtsi:614 */
			reg-names = "m_can",
			            "message_ram";                             /* in zephyr/dts/arm/st/h7/stm32h7.dtsi:615 */
			clocks = < &rcc 0xec 0x100 >;                          /* in zephyr/dts/arm/st/h7/stm32h7.dtsi:616 */
			interrupts = < 0x13 0x0 >,
			             < 0x15 0x0 >,
			             < 0x3f 0x0 >;                             /* in zephyr/dts/arm/st/h7/stm32h7.dtsi:617 */
			interrupt-names = "int0",
			                  "int1",
			                  "calib";                             /* in zephyr/dts/arm/st/h7/stm32h7.dtsi:618 */
			bosch,mram-cfg = < 0x0 0x1c 0x8 0x3 0x3 0x0 0x3 0x3 >; /* in zephyr/dts/arm/st/h7/stm32h7.dtsi:619 */
			status = "disabled";                                   /* in zephyr/dts/arm/st/h7/stm32h7.dtsi:620 */
		};

		/* node '/soc/can@4000a400' defined in zephyr/dts/arm/st/h7/stm32h7.dtsi:623 */
		fdcan2: can@4000a400 {
			compatible = "st,stm32h7-fdcan";                         /* in zephyr/dts/arm/st/h7/stm32h7.dtsi:624 */
			reg = < 0x4000a400 0x400 >,
			      < 0x4000ac00 0x6a0 >;                              /* in zephyr/dts/arm/st/h7/stm32h7.dtsi:625 */
			reg-names = "m_can",
			            "message_ram";                               /* in zephyr/dts/arm/st/h7/stm32h7.dtsi:626 */
			clocks = < &rcc 0xec 0x100 >;                            /* in zephyr/dts/arm/st/h7/stm32h7.dtsi:627 */
			interrupts = < 0x14 0x0 >,
			             < 0x16 0x0 >,
			             < 0x3f 0x0 >;                               /* in zephyr/dts/arm/st/h7/stm32h7.dtsi:628 */
			interrupt-names = "int0",
			                  "int1",
			                  "calib";                               /* in zephyr/dts/arm/st/h7/stm32h7.dtsi:629 */
			bosch,mram-cfg = < 0x350 0x1c 0x8 0x3 0x3 0x0 0x3 0x3 >; /* in zephyr/dts/arm/st/h7/stm32h7.dtsi:630 */
			status = "disabled";                                     /* in zephyr/dts/arm/st/h7/stm32h7.dtsi:631 */
		};

		/* node '/soc/timers@40010000' defined in zephyr/dts/arm/st/h7/stm32h7.dtsi:634 */
		timers1: timers@40010000 {
			compatible = "st,stm32-timers"; /* in zephyr/dts/arm/st/h7/stm32h7.dtsi:635 */
			reg = < 0x40010000 0x400 >;     /* in zephyr/dts/arm/st/h7/stm32h7.dtsi:636 */
			clocks = < &rcc 0xf0 0x1 >,
			         < &rcc 0x13 0xff >;    /* in zephyr/dts/arm/st/h7/stm32h7.dtsi:637 */
			resets = < &rctl 0x1300 >;      /* in zephyr/dts/arm/st/h7/stm32h7.dtsi:639 */
			interrupts = < 0x18 0x0 >,
			             < 0x19 0x0 >,
			             < 0x1a 0x0 >,
			             < 0x1b 0x0 >;      /* in zephyr/dts/arm/st/h7/stm32h7.dtsi:640 */
			interrupt-names = "brk",
			                  "up",
			                  "trgcom",
			                  "cc";         /* in zephyr/dts/arm/st/h7/stm32h7.dtsi:641 */
			st,prescaler = < 0x0 >;         /* in zephyr/dts/arm/st/h7/stm32h7.dtsi:642 */
			status = "disabled";            /* in zephyr/dts/arm/st/h7/stm32h7.dtsi:643 */

			/* node '/soc/timers@40010000/pwm' defined in zephyr/dts/arm/st/h7/stm32h7.dtsi:645 */
			pwm {
				compatible = "st,stm32-pwm"; /* in zephyr/dts/arm/st/h7/stm32h7.dtsi:646 */
				status = "disabled";         /* in zephyr/dts/arm/st/h7/stm32h7.dtsi:647 */
				#pwm-cells = < 0x3 >;        /* in zephyr/dts/arm/st/h7/stm32h7.dtsi:648 */
			};

			/* node '/soc/timers@40010000/counter' defined in zephyr/dts/arm/st/h7/stm32h7.dtsi:651 */
			counter {
				compatible = "st,stm32-counter"; /* in zephyr/dts/arm/st/h7/stm32h7.dtsi:652 */
				status = "disabled";             /* in zephyr/dts/arm/st/h7/stm32h7.dtsi:653 */
			};

			/* node '/soc/timers@40010000/qdec' defined in zephyr/dts/arm/st/h7/stm32h7.dtsi:656 */
			qdec {
				compatible = "st,stm32-qdec";    /* in zephyr/dts/arm/st/h7/stm32h7.dtsi:657 */
				st,input-filter-level = < 0x0 >; /* in zephyr/dts/arm/st/h7/stm32h7.dtsi:658 */
				status = "disabled";             /* in zephyr/dts/arm/st/h7/stm32h7.dtsi:659 */
			};
		};

		/* node '/soc/timers@40000000' defined in zephyr/dts/arm/st/h7/stm32h7.dtsi:663 */
		timers2: timers@40000000 {
			compatible = "st,stm32-timers"; /* in zephyr/dts/arm/st/h7/stm32h7.dtsi:664 */
			reg = < 0x40000000 0x400 >;     /* in zephyr/dts/arm/st/h7/stm32h7.dtsi:665 */
			clocks = < &rcc 0xe8 0x1 >,
			         < &rcc 0x12 0xff >;    /* in zephyr/dts/arm/st/h7/stm32h7.dtsi:666 */
			resets = < &rctl 0x1200 >;      /* in zephyr/dts/arm/st/h7/stm32h7.dtsi:668 */
			interrupts = < 0x1c 0x0 >;      /* in zephyr/dts/arm/st/h7/stm32h7.dtsi:669 */
			interrupt-names = "global";     /* in zephyr/dts/arm/st/h7/stm32h7.dtsi:670 */
			st,prescaler = < 0x0 >;         /* in zephyr/dts/arm/st/h7/stm32h7.dtsi:671 */
			status = "disabled";            /* in zephyr/dts/arm/st/h7/stm32h7.dtsi:672 */

			/* node '/soc/timers@40000000/pwm' defined in zephyr/dts/arm/st/h7/stm32h7.dtsi:674 */
			pwm {
				compatible = "st,stm32-pwm"; /* in zephyr/dts/arm/st/h7/stm32h7.dtsi:675 */
				status = "disabled";         /* in zephyr/dts/arm/st/h7/stm32h7.dtsi:676 */
				#pwm-cells = < 0x3 >;        /* in zephyr/dts/arm/st/h7/stm32h7.dtsi:677 */
			};

			/* node '/soc/timers@40000000/counter' defined in zephyr/dts/arm/st/h7/stm32h7.dtsi:680 */
			counter {
				compatible = "st,stm32-counter"; /* in zephyr/dts/arm/st/h7/stm32h7.dtsi:681 */
				status = "disabled";             /* in zephyr/dts/arm/st/h7/stm32h7.dtsi:682 */
			};

			/* node '/soc/timers@40000000/qdec' defined in zephyr/dts/arm/st/h7/stm32h7.dtsi:685 */
			qdec {
				compatible = "st,stm32-qdec";    /* in zephyr/dts/arm/st/h7/stm32h7.dtsi:686 */
				st,input-filter-level = < 0x0 >; /* in zephyr/dts/arm/st/h7/stm32h7.dtsi:687 */
				status = "disabled";             /* in zephyr/dts/arm/st/h7/stm32h7.dtsi:688 */
			};
		};

		/* node '/soc/timers@40000400' defined in zephyr/dts/arm/st/h7/stm32h7.dtsi:692 */
		timers3: timers@40000400 {
			compatible = "st,stm32-timers"; /* in zephyr/dts/arm/st/h7/stm32h7.dtsi:693 */
			reg = < 0x40000400 0x400 >;     /* in zephyr/dts/arm/st/h7/stm32h7.dtsi:694 */
			clocks = < &rcc 0xe8 0x2 >,
			         < &rcc 0x12 0xff >;    /* in zephyr/dts/arm/st/h7/stm32h7.dtsi:695 */
			resets = < &rctl 0x1201 >;      /* in zephyr/dts/arm/st/h7/stm32h7.dtsi:697 */
			interrupts = < 0x1d 0x0 >;      /* in zephyr/dts/arm/st/h7/stm32h7.dtsi:698 */
			interrupt-names = "global";     /* in zephyr/dts/arm/st/h7/stm32h7.dtsi:699 */
			st,prescaler = < 0x0 >;         /* in zephyr/dts/arm/st/h7/stm32h7.dtsi:700 */
			status = "disabled";            /* in zephyr/dts/arm/st/h7/stm32h7.dtsi:701 */

			/* node '/soc/timers@40000400/pwm' defined in zephyr/dts/arm/st/h7/stm32h7.dtsi:703 */
			pwm {
				compatible = "st,stm32-pwm"; /* in zephyr/dts/arm/st/h7/stm32h7.dtsi:704 */
				status = "disabled";         /* in zephyr/dts/arm/st/h7/stm32h7.dtsi:705 */
				#pwm-cells = < 0x3 >;        /* in zephyr/dts/arm/st/h7/stm32h7.dtsi:706 */
			};

			/* node '/soc/timers@40000400/counter' defined in zephyr/dts/arm/st/h7/stm32h7.dtsi:709 */
			counter {
				compatible = "st,stm32-counter"; /* in zephyr/dts/arm/st/h7/stm32h7.dtsi:710 */
				status = "disabled";             /* in zephyr/dts/arm/st/h7/stm32h7.dtsi:711 */
			};

			/* node '/soc/timers@40000400/qdec' defined in zephyr/dts/arm/st/h7/stm32h7.dtsi:714 */
			qdec {
				compatible = "st,stm32-qdec";    /* in zephyr/dts/arm/st/h7/stm32h7.dtsi:715 */
				st,input-filter-level = < 0x0 >; /* in zephyr/dts/arm/st/h7/stm32h7.dtsi:716 */
				status = "disabled";             /* in zephyr/dts/arm/st/h7/stm32h7.dtsi:717 */
			};
		};

		/* node '/soc/timers@40000800' defined in zephyr/dts/arm/st/h7/stm32h7.dtsi:721 */
		timers4: timers@40000800 {
			compatible = "st,stm32-timers"; /* in zephyr/dts/arm/st/h7/stm32h7.dtsi:722 */
			reg = < 0x40000800 0x400 >;     /* in zephyr/dts/arm/st/h7/stm32h7.dtsi:723 */
			clocks = < &rcc 0xe8 0x4 >,
			         < &rcc 0x12 0xff >;    /* in zephyr/dts/arm/st/h7/stm32h7.dtsi:724 */
			resets = < &rctl 0x1202 >;      /* in zephyr/dts/arm/st/h7/stm32h7.dtsi:726 */
			interrupts = < 0x1e 0x0 >;      /* in zephyr/dts/arm/st/h7/stm32h7.dtsi:727 */
			interrupt-names = "global";     /* in zephyr/dts/arm/st/h7/stm32h7.dtsi:728 */
			st,prescaler = < 0x0 >;         /* in zephyr/dts/arm/st/h7/stm32h7.dtsi:729 */
			status = "disabled";            /* in zephyr/dts/arm/st/h7/stm32h7.dtsi:730 */

			/* node '/soc/timers@40000800/pwm' defined in zephyr/dts/arm/st/h7/stm32h7.dtsi:732 */
			pwm {
				compatible = "st,stm32-pwm"; /* in zephyr/dts/arm/st/h7/stm32h7.dtsi:733 */
				status = "disabled";         /* in zephyr/dts/arm/st/h7/stm32h7.dtsi:734 */
				#pwm-cells = < 0x3 >;        /* in zephyr/dts/arm/st/h7/stm32h7.dtsi:735 */
			};

			/* node '/soc/timers@40000800/counter' defined in zephyr/dts/arm/st/h7/stm32h7.dtsi:738 */
			counter {
				compatible = "st,stm32-counter"; /* in zephyr/dts/arm/st/h7/stm32h7.dtsi:739 */
				status = "disabled";             /* in zephyr/dts/arm/st/h7/stm32h7.dtsi:740 */
			};

			/* node '/soc/timers@40000800/qdec' defined in zephyr/dts/arm/st/h7/stm32h7.dtsi:743 */
			qdec {
				compatible = "st,stm32-qdec";    /* in zephyr/dts/arm/st/h7/stm32h7.dtsi:744 */
				st,input-filter-level = < 0x0 >; /* in zephyr/dts/arm/st/h7/stm32h7.dtsi:745 */
				status = "disabled";             /* in zephyr/dts/arm/st/h7/stm32h7.dtsi:746 */
			};
		};

		/* node '/soc/timers@40000c00' defined in zephyr/dts/arm/st/h7/stm32h7.dtsi:750 */
		timers5: timers@40000c00 {
			compatible = "st,stm32-timers"; /* in zephyr/dts/arm/st/h7/stm32h7.dtsi:751 */
			reg = < 0x40000c00 0x400 >;     /* in zephyr/dts/arm/st/h7/stm32h7.dtsi:752 */
			clocks = < &rcc 0xe8 0x8 >,
			         < &rcc 0x12 0xff >;    /* in zephyr/dts/arm/st/h7/stm32h7.dtsi:753 */
			resets = < &rctl 0x1203 >;      /* in zephyr/dts/arm/st/h7/stm32h7.dtsi:755 */
			interrupts = < 0x32 0x0 >;      /* in zephyr/dts/arm/st/h7/stm32h7.dtsi:756 */
			interrupt-names = "global";     /* in zephyr/dts/arm/st/h7/stm32h7.dtsi:757 */
			st,prescaler = < 0x0 >;         /* in zephyr/dts/arm/st/h7/stm32h7.dtsi:758 */
			status = "disabled";            /* in zephyr/dts/arm/st/h7/stm32h7.dtsi:759 */

			/* node '/soc/timers@40000c00/pwm' defined in zephyr/dts/arm/st/h7/stm32h7.dtsi:761 */
			pwm {
				compatible = "st,stm32-pwm"; /* in zephyr/dts/arm/st/h7/stm32h7.dtsi:762 */
				status = "disabled";         /* in zephyr/dts/arm/st/h7/stm32h7.dtsi:763 */
				#pwm-cells = < 0x3 >;        /* in zephyr/dts/arm/st/h7/stm32h7.dtsi:764 */
			};

			/* node '/soc/timers@40000c00/counter' defined in zephyr/dts/arm/st/h7/stm32h7.dtsi:767 */
			counter {
				compatible = "st,stm32-counter"; /* in zephyr/dts/arm/st/h7/stm32h7.dtsi:768 */
				status = "disabled";             /* in zephyr/dts/arm/st/h7/stm32h7.dtsi:769 */
			};

			/* node '/soc/timers@40000c00/qdec' defined in zephyr/dts/arm/st/h7/stm32h7.dtsi:772 */
			qdec {
				compatible = "st,stm32-qdec";    /* in zephyr/dts/arm/st/h7/stm32h7.dtsi:773 */
				st,input-filter-level = < 0x0 >; /* in zephyr/dts/arm/st/h7/stm32h7.dtsi:774 */
				status = "disabled";             /* in zephyr/dts/arm/st/h7/stm32h7.dtsi:775 */
			};
		};

		/* node '/soc/timers@40001000' defined in zephyr/dts/arm/st/h7/stm32h7.dtsi:779 */
		timers6: timers@40001000 {
			compatible = "st,stm32-timers"; /* in zephyr/dts/arm/st/h7/stm32h7.dtsi:780 */
			reg = < 0x40001000 0x400 >;     /* in zephyr/dts/arm/st/h7/stm32h7.dtsi:781 */
			clocks = < &rcc 0xe8 0x10 >,
			         < &rcc 0x12 0xff >;    /* in zephyr/dts/arm/st/h7/stm32h7.dtsi:782 */
			resets = < &rctl 0x1204 >;      /* in zephyr/dts/arm/st/h7/stm32h7.dtsi:784 */
			interrupts = < 0x36 0x0 >;      /* in zephyr/dts/arm/st/h7/stm32h7.dtsi:785 */
			interrupt-names = "global";     /* in zephyr/dts/arm/st/h7/stm32h7.dtsi:786 */
			st,prescaler = < 0x0 >;         /* in zephyr/dts/arm/st/h7/stm32h7.dtsi:787 */
			status = "disabled";            /* in zephyr/dts/arm/st/h7/stm32h7.dtsi:788 */

			/* node '/soc/timers@40001000/counter' defined in zephyr/dts/arm/st/h7/stm32h7.dtsi:790 */
			counter {
				compatible = "st,stm32-counter"; /* in zephyr/dts/arm/st/h7/stm32h7.dtsi:791 */
				status = "disabled";             /* in zephyr/dts/arm/st/h7/stm32h7.dtsi:792 */
			};
		};

		/* node '/soc/timers@40001400' defined in zephyr/dts/arm/st/h7/stm32h7.dtsi:796 */
		timers7: timers@40001400 {
			compatible = "st,stm32-timers"; /* in zephyr/dts/arm/st/h7/stm32h7.dtsi:797 */
			reg = < 0x40001400 0x400 >;     /* in zephyr/dts/arm/st/h7/stm32h7.dtsi:798 */
			clocks = < &rcc 0xe8 0x20 >,
			         < &rcc 0x12 0xff >;    /* in zephyr/dts/arm/st/h7/stm32h7.dtsi:799 */
			resets = < &rctl 0x1205 >;      /* in zephyr/dts/arm/st/h7/stm32h7.dtsi:801 */
			interrupts = < 0x37 0x0 >;      /* in zephyr/dts/arm/st/h7/stm32h7.dtsi:802 */
			interrupt-names = "global";     /* in zephyr/dts/arm/st/h7/stm32h7.dtsi:803 */
			st,prescaler = < 0x0 >;         /* in zephyr/dts/arm/st/h7/stm32h7.dtsi:804 */
			status = "disabled";            /* in zephyr/dts/arm/st/h7/stm32h7.dtsi:805 */

			/* node '/soc/timers@40001400/counter' defined in zephyr/dts/arm/st/h7/stm32h7.dtsi:807 */
			counter {
				compatible = "st,stm32-counter"; /* in zephyr/dts/arm/st/h7/stm32h7.dtsi:808 */
				status = "disabled";             /* in zephyr/dts/arm/st/h7/stm32h7.dtsi:809 */
			};
		};

		/* node '/soc/timers@40010400' defined in zephyr/dts/arm/st/h7/stm32h7.dtsi:813 */
		timers8: timers@40010400 {
			compatible = "st,stm32-timers"; /* in zephyr/dts/arm/st/h7/stm32h7.dtsi:814 */
			reg = < 0x40010400 0x400 >;     /* in zephyr/dts/arm/st/h7/stm32h7.dtsi:815 */
			clocks = < &rcc 0xf0 0x2 >,
			         < &rcc 0x13 0xff >;    /* in zephyr/dts/arm/st/h7/stm32h7.dtsi:816 */
			resets = < &rctl 0x1301 >;      /* in zephyr/dts/arm/st/h7/stm32h7.dtsi:818 */
			interrupts = < 0x2b 0x0 >,
			             < 0x2c 0x0 >,
			             < 0x2d 0x0 >,
			             < 0x2e 0x0 >;      /* in zephyr/dts/arm/st/h7/stm32h7.dtsi:819 */
			interrupt-names = "brk",
			                  "up",
			                  "trgcom",
			                  "cc";         /* in zephyr/dts/arm/st/h7/stm32h7.dtsi:820 */
			st,prescaler = < 0x0 >;         /* in zephyr/dts/arm/st/h7/stm32h7.dtsi:821 */
			status = "disabled";            /* in zephyr/dts/arm/st/h7/stm32h7.dtsi:822 */

			/* node '/soc/timers@40010400/pwm' defined in zephyr/dts/arm/st/h7/stm32h7.dtsi:824 */
			pwm {
				compatible = "st,stm32-pwm"; /* in zephyr/dts/arm/st/h7/stm32h7.dtsi:825 */
				status = "disabled";         /* in zephyr/dts/arm/st/h7/stm32h7.dtsi:826 */
				#pwm-cells = < 0x3 >;        /* in zephyr/dts/arm/st/h7/stm32h7.dtsi:827 */
			};

			/* node '/soc/timers@40010400/counter' defined in zephyr/dts/arm/st/h7/stm32h7.dtsi:830 */
			counter {
				compatible = "st,stm32-counter"; /* in zephyr/dts/arm/st/h7/stm32h7.dtsi:831 */
				status = "disabled";             /* in zephyr/dts/arm/st/h7/stm32h7.dtsi:832 */
			};

			/* node '/soc/timers@40010400/qdec' defined in zephyr/dts/arm/st/h7/stm32h7.dtsi:835 */
			qdec {
				compatible = "st,stm32-qdec";    /* in zephyr/dts/arm/st/h7/stm32h7.dtsi:836 */
				st,input-filter-level = < 0x0 >; /* in zephyr/dts/arm/st/h7/stm32h7.dtsi:837 */
				status = "disabled";             /* in zephyr/dts/arm/st/h7/stm32h7.dtsi:838 */
			};
		};

		/* node '/soc/timers@40001800' defined in zephyr/dts/arm/st/h7/stm32h7.dtsi:842 */
		timers12: timers@40001800 {
			compatible = "st,stm32-timers"; /* in zephyr/dts/arm/st/h7/stm32h7.dtsi:843 */
			reg = < 0x40001800 0x400 >;     /* in zephyr/dts/arm/st/h7/stm32h7.dtsi:844 */
			clocks = < &rcc 0xe8 0x40 >,
			         < &rcc 0x12 0xff >;    /* in zephyr/dts/arm/st/h7/stm32h7.dtsi:845 */
			resets = < &rctl 0x1206 >;      /* in zephyr/dts/arm/st/h7/stm32h7.dtsi:847 */
			interrupts = < 0x2b 0x0 >;      /* in zephyr/dts/arm/st/h7/stm32h7.dtsi:848 */
			interrupt-names = "global";     /* in zephyr/dts/arm/st/h7/stm32h7.dtsi:849 */
			st,prescaler = < 0x0 >;         /* in zephyr/dts/arm/st/h7/stm32h7.dtsi:850 */
			status = "disabled";            /* in zephyr/dts/arm/st/h7/stm32h7.dtsi:851 */

			/* node '/soc/timers@40001800/pwm' defined in zephyr/dts/arm/st/h7/stm32h7.dtsi:853 */
			pwm {
				compatible = "st,stm32-pwm"; /* in zephyr/dts/arm/st/h7/stm32h7.dtsi:854 */
				status = "disabled";         /* in zephyr/dts/arm/st/h7/stm32h7.dtsi:855 */
				#pwm-cells = < 0x3 >;        /* in zephyr/dts/arm/st/h7/stm32h7.dtsi:856 */
			};

			/* node '/soc/timers@40001800/counter' defined in zephyr/dts/arm/st/h7/stm32h7.dtsi:859 */
			counter {
				compatible = "st,stm32-counter"; /* in zephyr/dts/arm/st/h7/stm32h7.dtsi:860 */
				status = "disabled";             /* in zephyr/dts/arm/st/h7/stm32h7.dtsi:861 */
			};
		};

		/* node '/soc/timers@40001c00' defined in zephyr/dts/arm/st/h7/stm32h7.dtsi:865 */
		timers13: timers@40001c00 {
			compatible = "st,stm32-timers"; /* in zephyr/dts/arm/st/h7/stm32h7.dtsi:866 */
			reg = < 0x40001c00 0x400 >;     /* in zephyr/dts/arm/st/h7/stm32h7.dtsi:867 */
			clocks = < &rcc 0xe8 0x80 >,
			         < &rcc 0x12 0xff >;    /* in zephyr/dts/arm/st/h7/stm32h7.dtsi:868 */
			resets = < &rctl 0x1207 >;      /* in zephyr/dts/arm/st/h7/stm32h7.dtsi:870 */
			interrupts = < 0x2c 0x0 >;      /* in zephyr/dts/arm/st/h7/stm32h7.dtsi:871 */
			interrupt-names = "global";     /* in zephyr/dts/arm/st/h7/stm32h7.dtsi:872 */
			st,prescaler = < 0x0 >;         /* in zephyr/dts/arm/st/h7/stm32h7.dtsi:873 */
			status = "disabled";            /* in zephyr/dts/arm/st/h7/stm32h7.dtsi:874 */

			/* node '/soc/timers@40001c00/pwm' defined in zephyr/dts/arm/st/h7/stm32h7.dtsi:876 */
			pwm {
				compatible = "st,stm32-pwm"; /* in zephyr/dts/arm/st/h7/stm32h7.dtsi:877 */
				status = "disabled";         /* in zephyr/dts/arm/st/h7/stm32h7.dtsi:878 */
				#pwm-cells = < 0x3 >;        /* in zephyr/dts/arm/st/h7/stm32h7.dtsi:879 */
			};

			/* node '/soc/timers@40001c00/counter' defined in zephyr/dts/arm/st/h7/stm32h7.dtsi:882 */
			counter {
				compatible = "st,stm32-counter"; /* in zephyr/dts/arm/st/h7/stm32h7.dtsi:883 */
				status = "disabled";             /* in zephyr/dts/arm/st/h7/stm32h7.dtsi:884 */
			};
		};

		/* node '/soc/timers@40002000' defined in zephyr/dts/arm/st/h7/stm32h7.dtsi:888 */
		timers14: timers@40002000 {
			compatible = "st,stm32-timers"; /* in zephyr/dts/arm/st/h7/stm32h7.dtsi:889 */
			reg = < 0x40002000 0x400 >;     /* in zephyr/dts/arm/st/h7/stm32h7.dtsi:890 */
			clocks = < &rcc 0xe8 0x100 >,
			         < &rcc 0x12 0xff >;    /* in zephyr/dts/arm/st/h7/stm32h7.dtsi:891 */
			resets = < &rctl 0x1208 >;      /* in zephyr/dts/arm/st/h7/stm32h7.dtsi:893 */
			interrupts = < 0x2d 0x0 >;      /* in zephyr/dts/arm/st/h7/stm32h7.dtsi:894 */
			interrupt-names = "global";     /* in zephyr/dts/arm/st/h7/stm32h7.dtsi:895 */
			st,prescaler = < 0x0 >;         /* in zephyr/dts/arm/st/h7/stm32h7.dtsi:896 */
			status = "disabled";            /* in zephyr/dts/arm/st/h7/stm32h7.dtsi:897 */

			/* node '/soc/timers@40002000/pwm' defined in zephyr/dts/arm/st/h7/stm32h7.dtsi:899 */
			pwm {
				compatible = "st,stm32-pwm"; /* in zephyr/dts/arm/st/h7/stm32h7.dtsi:900 */
				status = "disabled";         /* in zephyr/dts/arm/st/h7/stm32h7.dtsi:901 */
				#pwm-cells = < 0x3 >;        /* in zephyr/dts/arm/st/h7/stm32h7.dtsi:902 */
			};

			/* node '/soc/timers@40002000/counter' defined in zephyr/dts/arm/st/h7/stm32h7.dtsi:905 */
			counter {
				compatible = "st,stm32-counter"; /* in zephyr/dts/arm/st/h7/stm32h7.dtsi:906 */
				status = "disabled";             /* in zephyr/dts/arm/st/h7/stm32h7.dtsi:907 */
			};
		};

		/* node '/soc/timers@40014000' defined in zephyr/dts/arm/st/h7/stm32h7.dtsi:911 */
		timers15: timers@40014000 {
			compatible = "st,stm32-timers"; /* in zephyr/dts/arm/st/h7/stm32h7.dtsi:912 */
			reg = < 0x40014000 0x400 >;     /* in zephyr/dts/arm/st/h7/stm32h7.dtsi:913 */
			clocks = < &rcc 0xf0 0x10000 >,
			         < &rcc 0x13 0xff >;    /* in zephyr/dts/arm/st/h7/stm32h7.dtsi:914 */
			resets = < &rctl 0x1310 >;      /* in zephyr/dts/arm/st/h7/stm32h7.dtsi:916 */
			interrupts = < 0x74 0x0 >;      /* in zephyr/dts/arm/st/h7/stm32h7.dtsi:917 */
			interrupt-names = "global";     /* in zephyr/dts/arm/st/h7/stm32h7.dtsi:918 */
			st,prescaler = < 0x0 >;         /* in zephyr/dts/arm/st/h7/stm32h7.dtsi:919 */
			status = "disabled";            /* in zephyr/dts/arm/st/h7/stm32h7.dtsi:920 */

			/* node '/soc/timers@40014000/pwm' defined in zephyr/dts/arm/st/h7/stm32h7.dtsi:922 */
			pwm {
				compatible = "st,stm32-pwm"; /* in zephyr/dts/arm/st/h7/stm32h7.dtsi:923 */
				status = "disabled";         /* in zephyr/dts/arm/st/h7/stm32h7.dtsi:924 */
				#pwm-cells = < 0x3 >;        /* in zephyr/dts/arm/st/h7/stm32h7.dtsi:925 */
			};

			/* node '/soc/timers@40014000/counter' defined in zephyr/dts/arm/st/h7/stm32h7.dtsi:928 */
			counter {
				compatible = "st,stm32-counter"; /* in zephyr/dts/arm/st/h7/stm32h7.dtsi:929 */
				status = "disabled";             /* in zephyr/dts/arm/st/h7/stm32h7.dtsi:930 */
			};
		};

		/* node '/soc/timers@40014400' defined in zephyr/dts/arm/st/h7/stm32h7.dtsi:934 */
		timers16: timers@40014400 {
			compatible = "st,stm32-timers"; /* in zephyr/dts/arm/st/h7/stm32h7.dtsi:935 */
			reg = < 0x40014400 0x400 >;     /* in zephyr/dts/arm/st/h7/stm32h7.dtsi:936 */
			clocks = < &rcc 0xf0 0x20000 >,
			         < &rcc 0x13 0xff >;    /* in zephyr/dts/arm/st/h7/stm32h7.dtsi:937 */
			resets = < &rctl 0x1311 >;      /* in zephyr/dts/arm/st/h7/stm32h7.dtsi:939 */
			interrupts = < 0x75 0x0 >;      /* in zephyr/dts/arm/st/h7/stm32h7.dtsi:940 */
			interrupt-names = "global";     /* in zephyr/dts/arm/st/h7/stm32h7.dtsi:941 */
			st,prescaler = < 0x0 >;         /* in zephyr/dts/arm/st/h7/stm32h7.dtsi:942 */
			status = "disabled";            /* in zephyr/dts/arm/st/h7/stm32h7.dtsi:943 */

			/* node '/soc/timers@40014400/pwm' defined in zephyr/dts/arm/st/h7/stm32h7.dtsi:945 */
			pwm {
				compatible = "st,stm32-pwm"; /* in zephyr/dts/arm/st/h7/stm32h7.dtsi:946 */
				status = "disabled";         /* in zephyr/dts/arm/st/h7/stm32h7.dtsi:947 */
				#pwm-cells = < 0x3 >;        /* in zephyr/dts/arm/st/h7/stm32h7.dtsi:948 */
			};

			/* node '/soc/timers@40014400/counter' defined in zephyr/dts/arm/st/h7/stm32h7.dtsi:951 */
			counter {
				compatible = "st,stm32-counter"; /* in zephyr/dts/arm/st/h7/stm32h7.dtsi:952 */
				status = "disabled";             /* in zephyr/dts/arm/st/h7/stm32h7.dtsi:953 */
			};
		};

		/* node '/soc/timers@40014800' defined in zephyr/dts/arm/st/h7/stm32h7.dtsi:957 */
		timers17: timers@40014800 {
			compatible = "st,stm32-timers"; /* in zephyr/dts/arm/st/h7/stm32h7.dtsi:958 */
			reg = < 0x40014800 0x400 >;     /* in zephyr/dts/arm/st/h7/stm32h7.dtsi:959 */
			clocks = < &rcc 0xf0 0x40000 >,
			         < &rcc 0x13 0xff >;    /* in zephyr/dts/arm/st/h7/stm32h7.dtsi:960 */
			resets = < &rctl 0x1312 >;      /* in zephyr/dts/arm/st/h7/stm32h7.dtsi:962 */
			interrupts = < 0x76 0x0 >;      /* in zephyr/dts/arm/st/h7/stm32h7.dtsi:963 */
			interrupt-names = "global";     /* in zephyr/dts/arm/st/h7/stm32h7.dtsi:964 */
			st,prescaler = < 0x0 >;         /* in zephyr/dts/arm/st/h7/stm32h7.dtsi:965 */
			status = "disabled";            /* in zephyr/dts/arm/st/h7/stm32h7.dtsi:966 */

			/* node '/soc/timers@40014800/pwm' defined in zephyr/dts/arm/st/h7/stm32h7.dtsi:968 */
			pwm {
				compatible = "st,stm32-pwm"; /* in zephyr/dts/arm/st/h7/stm32h7.dtsi:969 */
				status = "disabled";         /* in zephyr/dts/arm/st/h7/stm32h7.dtsi:970 */
				#pwm-cells = < 0x3 >;        /* in zephyr/dts/arm/st/h7/stm32h7.dtsi:971 */
			};

			/* node '/soc/timers@40014800/counter' defined in zephyr/dts/arm/st/h7/stm32h7.dtsi:974 */
			counter {
				compatible = "st,stm32-counter"; /* in zephyr/dts/arm/st/h7/stm32h7.dtsi:975 */
				status = "disabled";             /* in zephyr/dts/arm/st/h7/stm32h7.dtsi:976 */
			};
		};

		/* node '/soc/timers@40002400' defined in zephyr/dts/arm/st/h7/stm32h7.dtsi:980 */
		lptim1: timers@40002400 {
			compatible = "st,stm32-lptim"; /* in zephyr/dts/arm/st/h7/stm32h7.dtsi:981 */
			clocks = < &rcc 0xe8 0x200 >;  /* in zephyr/dts/arm/st/h7/stm32h7.dtsi:982 */
			resets = < &rctl 0x1209 >;     /* in zephyr/dts/arm/st/h7/stm32h7.dtsi:983 */
			#address-cells = < 0x1 >;      /* in zephyr/dts/arm/st/h7/stm32h7.dtsi:984 */
			#size-cells = < 0x0 >;         /* in zephyr/dts/arm/st/h7/stm32h7.dtsi:985 */
			reg = < 0x40002400 0x400 >;    /* in zephyr/dts/arm/st/h7/stm32h7.dtsi:986 */
			interrupts = < 0x5d 0x1 >;     /* in zephyr/dts/arm/st/h7/stm32h7.dtsi:987 */
			interrupt-names = "wakeup";    /* in zephyr/dts/arm/st/h7/stm32h7.dtsi:988 */
			status = "disabled";           /* in zephyr/dts/arm/st/h7/stm32h7.dtsi:989 */
		};

		/* node '/soc/adc@40022000' defined in zephyr/dts/arm/st/h7/stm32h7.dtsi:992 */
		adc1: adc@40022000 {
			compatible = "st,stm32-adc";                                 /* in zephyr/dts/arm/st/h7/stm32h7.dtsi:993 */
			reg = < 0x40022000 0x400 >;                                  /* in zephyr/dts/arm/st/h7/stm32h7.dtsi:994 */
			clocks = < &rcc 0xd8 0x20 >;                                 /* in zephyr/dts/arm/st/h7/stm32h7.dtsi:995 */
			clock-names = "adcx";                                        /* in zephyr/dts/arm/st/h7/stm32h7.dtsi:996 */
			interrupts = < 0x12 0x0 >;                                   /* in zephyr/dts/arm/st/h7/stm32h7.dtsi:997 */
			#io-channel-cells = < 0x1 >;                                 /* in zephyr/dts/arm/st/h7/stm32h7.dtsi:998 */
			st,adc-resolutions = < 0x10 0xe 0xc 0xa 0x8 >;               /* in zephyr/dts/arm/st/h7/stm32h7.dtsi:999 */
			sampling-times = < 0x2 0x3 0x9 0x11 0x21 0x41 0x184 0x32b >; /* in zephyr/dts/arm/st/h7/stm32h7.dtsi:1000 */
			st,adc-sequencer = "programmable";                           /* in zephyr/dts/arm/st/h7/stm32h7.dtsi:1001 */
			st,adc-oversampler = "extended";                             /* in zephyr/dts/arm/st/h7/stm32h7.dtsi:1002 */
			st,adc-internal-regulator = "startup-hw-status";             /* in zephyr/dts/arm/st/h7/stm32h7.dtsi:1003 */
			st,adc-has-deep-powerdown;                                   /* in zephyr/dts/arm/st/h7/stm32h7.dtsi:1004 */
			st,adc-has-channel-preselection;                             /* in zephyr/dts/arm/st/h7/stm32h7.dtsi:1005 */
			st,adc-has-differential-support;                             /* in zephyr/dts/arm/st/h7/stm32h7.dtsi:1006 */
			st,adc-has-injected-support;                                 /* in zephyr/dts/arm/st/h7/stm32h7.dtsi:1007 */
			status = "disabled";                                         /* in zephyr/dts/arm/st/h7/stm32h7.dtsi:1008 */
		};

		/* node '/soc/adc@40022100' defined in zephyr/dts/arm/st/h7/stm32h7.dtsi:1011 */
		adc2: adc@40022100 {
			compatible = "st,stm32-adc";                                 /* in zephyr/dts/arm/st/h7/stm32h7.dtsi:1012 */
			reg = < 0x40022100 0x400 >;                                  /* in zephyr/dts/arm/st/h7/stm32h7.dtsi:1013 */
			clocks = < &rcc 0xd8 0x20 >;                                 /* in zephyr/dts/arm/st/h7/stm32h7.dtsi:1014 */
			clock-names = "adcx";                                        /* in zephyr/dts/arm/st/h7/stm32h7.dtsi:1015 */
			interrupts = < 0x12 0x0 >;                                   /* in zephyr/dts/arm/st/h7/stm32h7.dtsi:1016 */
			#io-channel-cells = < 0x1 >;                                 /* in zephyr/dts/arm/st/h7/stm32h7.dtsi:1017 */
			st,adc-resolutions = < 0x10 0xe 0xc 0xa 0x8 >;               /* in zephyr/dts/arm/st/h7/stm32h7.dtsi:1018 */
			sampling-times = < 0x2 0x3 0x9 0x11 0x21 0x41 0x184 0x32b >; /* in zephyr/dts/arm/st/h7/stm32h7.dtsi:1019 */
			st,adc-sequencer = "programmable";                           /* in zephyr/dts/arm/st/h7/stm32h7.dtsi:1020 */
			st,adc-oversampler = "extended";                             /* in zephyr/dts/arm/st/h7/stm32h7.dtsi:1021 */
			st,adc-internal-regulator = "startup-hw-status";             /* in zephyr/dts/arm/st/h7/stm32h7.dtsi:1022 */
			st,adc-has-deep-powerdown;                                   /* in zephyr/dts/arm/st/h7/stm32h7.dtsi:1023 */
			st,adc-has-channel-preselection;                             /* in zephyr/dts/arm/st/h7/stm32h7.dtsi:1024 */
			st,adc-has-differential-support;                             /* in zephyr/dts/arm/st/h7/stm32h7.dtsi:1025 */
			st,adc-has-injected-support;                                 /* in zephyr/dts/arm/st/h7/stm32h7.dtsi:1026 */
			status = "disabled";                                         /* in zephyr/dts/arm/st/h7/stm32h7.dtsi:1027 */
		};

		/* node '/soc/adc@40022300' defined in zephyr/dts/arm/st/h7/stm32h7.dtsi:1031 */
		adc1_2: adc@40022300 {
			compatible = "st,stm32-adc";                                 /* in zephyr/dts/arm/st/h7/stm32h7.dtsi:1032 */
			reg = < 0x40022300 0x400 >;                                  /* in zephyr/dts/arm/st/h7/stm32h7.dtsi:1033 */
			clocks = < &rcc 0xd8 0x20 >;                                 /* in zephyr/dts/arm/st/h7/stm32h7.dtsi:1034 */
			clock-names = "adcx";                                        /* in zephyr/dts/arm/st/h7/stm32h7.dtsi:1035 */
			interrupts = < 0x12 0x0 >;                                   /* in zephyr/dts/arm/st/h7/stm32h7.dtsi:1036 */
			#io-channel-cells = < 0x1 >;                                 /* in zephyr/dts/arm/st/h7/stm32h7.dtsi:1037 */
			st,adc-resolutions = < 0x10 0xe 0xc 0xa 0x8 >;               /* in zephyr/dts/arm/st/h7/stm32h7.dtsi:1038 */
			sampling-times = < 0x2 0x3 0x9 0x11 0x21 0x41 0x184 0x32b >; /* in zephyr/dts/arm/st/h7/stm32h7.dtsi:1039 */
			st,adc-sequencer = "programmable";                           /* in zephyr/dts/arm/st/h7/stm32h7.dtsi:1040 */
			st,adc-oversampler = "extended";                             /* in zephyr/dts/arm/st/h7/stm32h7.dtsi:1041 */
			st,adc-internal-regulator = "startup-hw-status";             /* in zephyr/dts/arm/st/h7/stm32h7.dtsi:1042 */
			st,adc-has-deep-powerdown;                                   /* in zephyr/dts/arm/st/h7/stm32h7.dtsi:1043 */
			st,adc-has-channel-preselection;                             /* in zephyr/dts/arm/st/h7/stm32h7.dtsi:1044 */
			st,adc-has-differential-support;                             /* in zephyr/dts/arm/st/h7/stm32h7.dtsi:1045 */
			st,adc-has-injected-support;                                 /* in zephyr/dts/arm/st/h7/stm32h7.dtsi:1046 */
			status = "disabled";                                         /* in zephyr/dts/arm/st/h7/stm32h7.dtsi:1047 */
		};

		/* node '/soc/adc@58026000' defined in zephyr/dts/arm/st/h7/stm32h7.dtsi:1050 */
		adc3: adc@58026000 {
			compatible = "st,stm32-adc";                                 /* in zephyr/dts/arm/st/h7/stm32h7.dtsi:1051 */
			reg = < 0x58026000 0x400 >;                                  /* in zephyr/dts/arm/st/h7/stm32h7.dtsi:1052 */
			clocks = < &rcc 0xe0 0x1000000 >;                            /* in zephyr/dts/arm/st/h7/stm32h7.dtsi:1053 */
			clock-names = "adcx";                                        /* in zephyr/dts/arm/st/h7/stm32h7.dtsi:1054 */
			interrupts = < 0x7f 0x0 >;                                   /* in zephyr/dts/arm/st/h7/stm32h7.dtsi:1055 */
			#io-channel-cells = < 0x1 >;                                 /* in zephyr/dts/arm/st/h7/stm32h7.dtsi:1056 */
			st,adc-resolutions = < 0x10 0xe 0xc 0xa 0x8 >;               /* in zephyr/dts/arm/st/h7/stm32h7.dtsi:1057 */
			sampling-times = < 0x2 0x3 0x9 0x11 0x21 0x41 0x184 0x32b >; /* in zephyr/dts/arm/st/h7/stm32h7.dtsi:1058 */
			st,adc-sequencer = "programmable";                           /* in zephyr/dts/arm/st/h7/stm32h7.dtsi:1059 */
			st,adc-oversampler = "extended";                             /* in zephyr/dts/arm/st/h7/stm32h7.dtsi:1060 */
			st,adc-internal-regulator = "startup-hw-status";             /* in zephyr/dts/arm/st/h7/stm32h7.dtsi:1061 */
			st,adc-has-deep-powerdown;                                   /* in zephyr/dts/arm/st/h7/stm32h7.dtsi:1062 */
			st,adc-has-channel-preselection;                             /* in zephyr/dts/arm/st/h7/stm32h7.dtsi:1063 */
			st,adc-has-differential-support;                             /* in zephyr/dts/arm/st/h7/stm32h7.dtsi:1064 */
			st,adc-has-injected-support;                                 /* in zephyr/dts/arm/st/h7/stm32h7.dtsi:1065 */
			status = "disabled";                                         /* in zephyr/dts/arm/st/h7/stm32h7.dtsi:1066 */
			phandle = < 0x14 >;                                          /* in zephyr/dts/arm/st/h7/stm32h7.dtsi:1303 */
		};

		/* node '/soc/dac@40007400' defined in zephyr/dts/arm/st/h7/stm32h7.dtsi:1069 */
		dac1: dac@40007400 {
			compatible = "st,stm32-dac";       /* in zephyr/dts/arm/st/h7/stm32h7.dtsi:1070 */
			reg = < 0x40007400 0x400 >;        /* in zephyr/dts/arm/st/h7/stm32h7.dtsi:1071 */
			clocks = < &rcc 0xe8 0x20000000 >; /* in zephyr/dts/arm/st/h7/stm32h7.dtsi:1072 */
			status = "disabled";               /* in zephyr/dts/arm/st/h7/stm32h7.dtsi:1073 */
			#io-channel-cells = < 0x1 >;       /* in zephyr/dts/arm/st/h7/stm32h7.dtsi:1074 */
		};

		/* node '/soc/dma@40020000' defined in zephyr/dts/arm/st/h7/stm32h7.dtsi:1077 */
		dma1: dma@40020000 {
			compatible = "st,stm32-dma-v1"; /* in zephyr/dts/arm/st/h7/stm32h7.dtsi:1078 */
			#dma-cells = < 0x4 >;           /* in zephyr/dts/arm/st/h7/stm32h7.dtsi:1079 */
			reg = < 0x40020000 0x400 >;     /* in zephyr/dts/arm/st/h7/stm32h7.dtsi:1080 */
			interrupts = < 0xb 0x0 >,
			             < 0xc 0x0 >,
			             < 0xd 0x0 >,
			             < 0xe 0x0 >,
			             < 0xf 0x0 >,
			             < 0x10 0x0 >,
			             < 0x11 0x0 >,
			             < 0x2f 0x0 >;      /* in zephyr/dts/arm/st/h7/stm32h7.dtsi:1081 */
			clocks = < &rcc 0xd8 0x1 >;     /* in zephyr/dts/arm/st/h7/stm32h7.dtsi:1083 */
			st,mem2mem;                     /* in zephyr/dts/arm/st/h7/stm32h7.dtsi:1084 */
			dma-offset = < 0x0 >;           /* in zephyr/dts/arm/st/h7/stm32h7.dtsi:1085 */
			dma-requests = < 0x8 >;         /* in zephyr/dts/arm/st/h7/stm32h7.dtsi:1086 */
			status = "disabled";            /* in zephyr/dts/arm/st/h7/stm32h7.dtsi:1087 */
			phandle = < 0xf >;              /* in zephyr/dts/arm/st/h7/stm32h7.dtsi:1237 */
		};

		/* node '/soc/dma@40020400' defined in zephyr/dts/arm/st/h7/stm32h7.dtsi:1090 */
		dma2: dma@40020400 {
			compatible = "st,stm32-dma-v1"; /* in zephyr/dts/arm/st/h7/stm32h7.dtsi:1091 */
			#dma-cells = < 0x4 >;           /* in zephyr/dts/arm/st/h7/stm32h7.dtsi:1092 */
			reg = < 0x40020400 0x400 >;     /* in zephyr/dts/arm/st/h7/stm32h7.dtsi:1093 */
			interrupts = < 0x38 0x0 >,
			             < 0x39 0x0 >,
			             < 0x3a 0x0 >,
			             < 0x3b 0x0 >,
			             < 0x3c 0x0 >,
			             < 0x44 0x0 >,
			             < 0x45 0x0 >,
			             < 0x46 0x0 >;      /* in zephyr/dts/arm/st/h7/stm32h7.dtsi:1094 */
			clocks = < &rcc 0xd8 0x2 >;     /* in zephyr/dts/arm/st/h7/stm32h7.dtsi:1096 */
			st,mem2mem;                     /* in zephyr/dts/arm/st/h7/stm32h7.dtsi:1097 */
			dma-offset = < 0x8 >;           /* in zephyr/dts/arm/st/h7/stm32h7.dtsi:1098 */
			dma-requests = < 0x8 >;         /* in zephyr/dts/arm/st/h7/stm32h7.dtsi:1099 */
			status = "disabled";            /* in zephyr/dts/arm/st/h7/stm32h7.dtsi:1100 */
		};

		/* node '/soc/bdma@58025400' defined in zephyr/dts/arm/st/h7/stm32h7.dtsi:1103 */
		bdma1: bdma@58025400 {
			compatible = "st,stm32-bdma";    /* in zephyr/dts/arm/st/h7/stm32h7.dtsi:1104 */
			#dma-cells = < 0x4 >;            /* in zephyr/dts/arm/st/h7/stm32h7.dtsi:1105 */
			reg = < 0x58025400 0x400 >;      /* in zephyr/dts/arm/st/h7/stm32h7.dtsi:1106 */
			interrupts = < 0x81 0x0 >,
			             < 0x82 0x0 >,
			             < 0x83 0x0 >,
			             < 0x84 0x0 >,
			             < 0x85 0x0 >,
			             < 0x86 0x0 >,
			             < 0x87 0x0 >,
			             < 0x88 0x0 >;       /* in zephyr/dts/arm/st/h7/stm32h7.dtsi:1107 */
			clocks = < &rcc 0xe0 0x200000 >; /* in zephyr/dts/arm/st/h7/stm32h7.dtsi:1109 */
			st,mem2mem;                      /* in zephyr/dts/arm/st/h7/stm32h7.dtsi:1110 */
			dma-offset = < 0x0 >;            /* in zephyr/dts/arm/st/h7/stm32h7.dtsi:1111 */
			dma-requests = < 0x8 >;          /* in zephyr/dts/arm/st/h7/stm32h7.dtsi:1112 */
			status = "disabled";             /* in zephyr/dts/arm/st/h7/stm32h7.dtsi:1113 */
		};

		/* node '/soc/dmamux@40020800' defined in zephyr/dts/arm/st/h7/stm32h7.dtsi:1116 */
		dmamux1: dmamux@40020800 {
			compatible = "st,stm32-dmamux"; /* in zephyr/dts/arm/st/h7/stm32h7.dtsi:1117 */
			#dma-cells = < 0x3 >;           /* in zephyr/dts/arm/st/h7/stm32h7.dtsi:1118 */
			reg = < 0x40020800 0x400 >;     /* in zephyr/dts/arm/st/h7/stm32h7.dtsi:1119 */
			interrupts = < 0x66 0x0 >;      /* in zephyr/dts/arm/st/h7/stm32h7.dtsi:1120 */
			clocks = < &rcc 0xd8 0x1 >;     /* in zephyr/dts/arm/st/h7/stm32h7.dtsi:1122 */
			dma-channels = < 0x10 >;        /* in zephyr/dts/arm/st/h7/stm32h7.dtsi:1123 */
			dma-generators = < 0x8 >;       /* in zephyr/dts/arm/st/h7/stm32h7.dtsi:1124 */
			status = "disabled";            /* in zephyr/dts/arm/st/h7/stm32h7.dtsi:1125 */
			dma-requests = < 0x6b >;        /* in zephyr/dts/arm/st/h7/stm32h742.dtsi:25 */
			phandle = < 0x7 >;              /* in zephyr/dts/arm/st/h7/stm32h7.dtsi:577 */
		};

		/* node '/soc/dmamux@58025800' defined in zephyr/dts/arm/st/h7/stm32h7.dtsi:1132 */
		dmamux2: dmamux@58025800 {
			compatible = "st,stm32-dmamux";  /* in zephyr/dts/arm/st/h7/stm32h7.dtsi:1133 */
			#dma-cells = < 0x3 >;            /* in zephyr/dts/arm/st/h7/stm32h7.dtsi:1134 */
			reg = < 0x58025800 0x400 >;      /* in zephyr/dts/arm/st/h7/stm32h7.dtsi:1135 */
			interrupts = < 0x80 0x0 >;       /* in zephyr/dts/arm/st/h7/stm32h7.dtsi:1136 */
			clocks = < &rcc 0xe0 0x200000 >; /* in zephyr/dts/arm/st/h7/stm32h7.dtsi:1138 */
			dma-channels = < 0x8 >;          /* in zephyr/dts/arm/st/h7/stm32h7.dtsi:1139 */
			dma-generators = < 0x8 >;        /* in zephyr/dts/arm/st/h7/stm32h7.dtsi:1140 */
			status = "disabled";             /* in zephyr/dts/arm/st/h7/stm32h7.dtsi:1141 */
			dma-requests = < 0xc >;          /* in zephyr/dts/arm/st/h7/stm32h742.dtsi:29 */
		};

		/* node '/soc/rng@48021800' defined in zephyr/dts/arm/st/h7/stm32h7.dtsi:1148 */
		rng: rng@48021800 {
			compatible = "st,stm32-rng"; /* in zephyr/dts/arm/st/h7/stm32h7.dtsi:1149 */
			reg = < 0x48021800 0x400 >;  /* in zephyr/dts/arm/st/h7/stm32h7.dtsi:1150 */
			clocks = < &rcc 0xdc 0x40 >; /* in zephyr/dts/arm/st/h7/stm32h7.dtsi:1151 */
			interrupts = < 0x50 0x0 >;   /* in zephyr/dts/arm/st/h7/stm32h7.dtsi:1152 */
			status = "disabled";         /* in zephyr/dts/arm/st/h7/stm32h7.dtsi:1153 */
		};

		/* node '/soc/sdmmc@52007000' defined in zephyr/dts/arm/st/h7/stm32h7.dtsi:1156 */
		sdmmc1: sdmmc@52007000 {
			compatible = "st,stm32-sdmmc";  /* in zephyr/dts/arm/st/h7/stm32h7.dtsi:1157 */
			reg = < 0x52007000 0x400 >;     /* in zephyr/dts/arm/st/h7/stm32h7.dtsi:1158 */
			clocks = < &rcc 0xd4 0x10000 >,
			         < &rcc 0x9 0x10004c >; /* in zephyr/dts/arm/st/h7/stm32h7.dtsi:1159 */
			resets = < &rctl 0xf90 >;       /* in zephyr/dts/arm/st/h7/stm32h7.dtsi:1161 */
			interrupts = < 0x31 0x0 >;      /* in zephyr/dts/arm/st/h7/stm32h7.dtsi:1162 */
			status = "disabled";            /* in zephyr/dts/arm/st/h7/stm32h7.dtsi:1163 */
		};

		/* node '/soc/sdmmc@48022400' defined in zephyr/dts/arm/st/h7/stm32h7.dtsi:1166 */
		sdmmc2: sdmmc@48022400 {
			compatible = "st,stm32-sdmmc";  /* in zephyr/dts/arm/st/h7/stm32h7.dtsi:1167 */
			reg = < 0x48022400 0x400 >;     /* in zephyr/dts/arm/st/h7/stm32h7.dtsi:1168 */
			clocks = < &rcc 0xdc 0x200 >,
			         < &rcc 0x9 0x10004c >; /* in zephyr/dts/arm/st/h7/stm32h7.dtsi:1169 */
			resets = < &rctl 0x1089 >;      /* in zephyr/dts/arm/st/h7/stm32h7.dtsi:1171 */
			interrupts = < 0x7c 0x0 >;      /* in zephyr/dts/arm/st/h7/stm32h7.dtsi:1172 */
			status = "disabled";            /* in zephyr/dts/arm/st/h7/stm32h7.dtsi:1173 */
		};

		/* node '/soc/ethernet@40028000' defined in zephyr/dts/arm/st/h7/stm32h7.dtsi:1176 */
		ethernet@40028000 {
			reg = < 0x40028000 0x8000 >;                 /* in zephyr/dts/arm/st/h7/stm32h7.dtsi:1177 */
			compatible = "st,stm32-ethernet-controller"; /* in zephyr/dts/arm/st/h7/stm32h7.dtsi:1178 */
			clock-names = "stm-eth",
			              "mac-clk-tx",
			              "mac-clk-rx";                  /* in zephyr/dts/arm/st/h7/stm32h7.dtsi:1179 */
			clocks = < &rcc 0xd8 0x8000 >,
			         < &rcc 0xd8 0x10000 >,
			         < &rcc 0xd8 0x20000 >;              /* in zephyr/dts/arm/st/h7/stm32h7.dtsi:1180 */

			/* node '/soc/ethernet@40028000/ethernet' defined in zephyr/dts/arm/st/h7/stm32h7.dtsi:1184 */
			mac: ethernet {
				compatible = "st,stm32h7-ethernet",
				             "st,stm32-ethernet";   /* in zephyr/dts/arm/st/h7/stm32h7.dtsi:1185 */
				interrupts = < 0x3d 0x0 >;          /* in zephyr/dts/arm/st/h7/stm32h7.dtsi:1186 */
				status = "disabled";                /* in zephyr/dts/arm/st/h7/stm32h7.dtsi:1188 */
				memory-regions = < &sram3 >;        /* in zephyr/dts/arm/st/h7/stm32h743.dtsi:41 */
			};

			/* node '/soc/ethernet@40028000/mdio' defined in zephyr/dts/arm/st/h7/stm32h7.dtsi:1191 */
			mdio: mdio {
				compatible = "st,stm32-mdio"; /* in zephyr/dts/arm/st/h7/stm32h7.dtsi:1192 */
				#address-cells = < 0x1 >;     /* in zephyr/dts/arm/st/h7/stm32h7.dtsi:1193 */
				#size-cells = < 0x0 >;        /* in zephyr/dts/arm/st/h7/stm32h7.dtsi:1194 */
				status = "disabled";          /* in zephyr/dts/arm/st/h7/stm32h7.dtsi:1195 */
			};
		};

		/* node '/soc/memory-controller@52004000' defined in zephyr/dts/arm/st/h7/stm32h7.dtsi:1199 */
		fmc: memory-controller@52004000 {
			compatible = "st,stm32h7-fmc"; /* in zephyr/dts/arm/st/h7/stm32h7.dtsi:1200 */
			reg = < 0x52004000 0x400 >;    /* in zephyr/dts/arm/st/h7/stm32h7.dtsi:1201 */
			clocks = < &rcc 0xd4 0x1000 >; /* in zephyr/dts/arm/st/h7/stm32h7.dtsi:1202 */
			status = "disabled";           /* in zephyr/dts/arm/st/h7/stm32h7.dtsi:1203 */

			/* node '/soc/memory-controller@52004000/sdram' defined in zephyr/dts/arm/st/h7/stm32h7.dtsi:1205 */
			sdram: sdram {
				compatible = "st,stm32-fmc-sdram"; /* in zephyr/dts/arm/st/h7/stm32h7.dtsi:1206 */
				#address-cells = < 0x1 >;          /* in zephyr/dts/arm/st/h7/stm32h7.dtsi:1207 */
				#size-cells = < 0x0 >;             /* in zephyr/dts/arm/st/h7/stm32h7.dtsi:1208 */
				status = "disabled";               /* in zephyr/dts/arm/st/h7/stm32h7.dtsi:1209 */
			};
		};

		/* node '/soc/memory@38800000' defined in zephyr/dts/arm/st/h7/stm32h7.dtsi:1213 */
		backup_sram: memory@38800000 {
			compatible = "zephyr,memory-region",
			             "st,stm32-backup-sram";  /* in zephyr/dts/arm/st/h7/stm32h7.dtsi:1214 */
			reg = < 0x38800000 0x1000 >;          /* in zephyr/dts/arm/st/h7/stm32h7.dtsi:1215 */
			clocks = < &rcc 0xe0 0x10000000 >;    /* in zephyr/dts/arm/st/h7/stm32h7.dtsi:1216 */
			zephyr,memory-region = "BACKUP_SRAM"; /* in zephyr/dts/arm/st/h7/stm32h7.dtsi:1217 */
			status = "disabled";                  /* in zephyr/dts/arm/st/h7/stm32h7.dtsi:1218 */
		};

		/* node '/soc/spi@52005000' defined in zephyr/dts/arm/st/h7/stm32h7.dtsi:1221 */
		quadspi: spi@52005000 {
			compatible = "st,stm32-qspi";                                                                   /* in zephyr/dts/arm/st/h7/stm32h7.dtsi:1222 */
			#address-cells = < 0x1 >;                                                                       /* in zephyr/dts/arm/st/h7/stm32h7.dtsi:1223 */
			#size-cells = < 0x0 >;                                                                          /* in zephyr/dts/arm/st/h7/stm32h7.dtsi:1224 */
			reg = < 0x52005000 0x1000 >,
			      < 0x90000000 0x10000000 >;                                                                /* in zephyr/dts/arm/st/h7/stm32h7.dtsi:1225 */
			interrupts = < 0x5c 0x0 >;                                                                      /* in zephyr/dts/arm/st/h7/stm32h7.dtsi:1226 */
			clocks = < &rcc 0xd4 0x4000 >;                                                                  /* in zephyr/dts/arm/st/h7/stm32h7.dtsi:1227 */
			pinctrl-names = "default";                                                                      /* in ../Projects/stm32_system_on_module/fw/som/boards/hagzey/som/som.dts:94 */
			pinctrl-0 = < &quadspi_clk_pf10 &quadspi_bk1_ncs_pb10 &quadspi_bk1_io0_pf8 &quadspi_bk1_io1_pf9
			              &quadspi_bk1_io2_pe2 &quadspi_bk1_io3_pf6 >;                                      /* in ../Projects/stm32_system_on_module/fw/som/boards/hagzey/som/som.dts:95 */
			flash-id = < 0x1 >;                                                                             /* in ../Projects/stm32_system_on_module/fw/som/boards/hagzey/som/som.dts:98 */
			status = "okay";                                                                                /* in ../Projects/stm32_system_on_module/fw/som/boards/hagzey/som/som.dts:99 */

			/* node '/soc/spi@52005000/qspi-nor-flash@0' defined in ../Projects/stm32_system_on_module/fw/som/boards/hagzey/som/som.dts:101 */
			at25ff161a: qspi-nor-flash@0 {
				compatible = "st,stm32-qspi-nor";   /* in ../Projects/stm32_system_on_module/fw/som/boards/hagzey/som/som.dts:102 */
				reg = < 0x0 >;                      /* in ../Projects/stm32_system_on_module/fw/som/boards/hagzey/som/som.dts:103 */
				size = < 0x200000 >;                /* in ../Projects/stm32_system_on_module/fw/som/boards/hagzey/som/som.dts:104 */
				qspi-max-frequency = < 0x2625a00 >; /* in ../Projects/stm32_system_on_module/fw/som/boards/hagzey/som/som.dts:105 */
				cs-high-time = < 0x2 >;             /* in ../Projects/stm32_system_on_module/fw/som/boards/hagzey/som/som.dts:106 */
				spi-bus-width = < 0x4 >;            /* in ../Projects/stm32_system_on_module/fw/som/boards/hagzey/som/som.dts:107 */
				writeoc = "PP_1_1_4";               /* in ../Projects/stm32_system_on_module/fw/som/boards/hagzey/som/som.dts:108 */
				status = "okay";                    /* in ../Projects/stm32_system_on_module/fw/som/boards/hagzey/som/som.dts:109 */

				/* node '/soc/spi@52005000/qspi-nor-flash@0/partitions' defined in ../Projects/stm32_system_on_module/fw/som/boards/hagzey/som/som.dts:111 */
				partitions {
					compatible = "fixed-partitions"; /* in ../Projects/stm32_system_on_module/fw/som/boards/hagzey/som/som.dts:112 */
					#address-cells = < 0x1 >;        /* in ../Projects/stm32_system_on_module/fw/som/boards/hagzey/som/som.dts:113 */
					#size-cells = < 0x1 >;           /* in ../Projects/stm32_system_on_module/fw/som/boards/hagzey/som/som.dts:114 */

					/* node '/soc/spi@52005000/qspi-nor-flash@0/partitions/partition@0' defined in ../Projects/stm32_system_on_module/fw/som/boards/hagzey/som/som.dts:116 */
					slot0_partition: partition@0 {
						reg = < 0x0 0x200000 >; /* in ../Projects/stm32_system_on_module/fw/som/boards/hagzey/som/som.dts:117 */
					};
				};
			};
		};

		/* node '/soc/dcmi@48020000' defined in zephyr/dts/arm/st/h7/stm32h7.dtsi:1231 */
		dcmi: dcmi@48020000 {
			compatible = "st,stm32-dcmi";          /* in zephyr/dts/arm/st/h7/stm32h7.dtsi:1232 */
			reg = < 0x48020000 0x400 >;            /* in zephyr/dts/arm/st/h7/stm32h7.dtsi:1233 */
			interrupts = < 0x4e 0x0 >;             /* in zephyr/dts/arm/st/h7/stm32h7.dtsi:1234 */
			interrupt-names = "dcmi";              /* in zephyr/dts/arm/st/h7/stm32h7.dtsi:1235 */
			clocks = < &rcc 0xdc 0x1 >;            /* in zephyr/dts/arm/st/h7/stm32h7.dtsi:1236 */
			dmas = < &dma1 0x1 0x4b 0x24480 0x0 >; /* in zephyr/dts/arm/st/h7/stm32h7.dtsi:1237 */
			status = "disabled";                   /* in zephyr/dts/arm/st/h7/stm32h7.dtsi:1241 */
		};

		/* node '/soc/sai1@40015804' defined in zephyr/dts/arm/st/h7/stm32h7.dtsi:1244 */
		sai1_a: sai1@40015804 {
			compatible = "st,stm32-sai";           /* in zephyr/dts/arm/st/h7/stm32h7.dtsi:1245 */
			#address-cells = < 0x1 >;              /* in zephyr/dts/arm/st/h7/stm32h7.dtsi:1246 */
			#size-cells = < 0x0 >;                 /* in zephyr/dts/arm/st/h7/stm32h7.dtsi:1247 */
			reg = < 0x40015804 0x20 >;             /* in zephyr/dts/arm/st/h7/stm32h7.dtsi:1248 */
			clocks = < &rcc 0xf0 0x400000 >,
			         < &rcc 0xb 0x1400050 >;       /* in zephyr/dts/arm/st/h7/stm32h7.dtsi:1249 */
			dmas = < &dma1 0x2 0x57 0x22800 0x0 >; /* in zephyr/dts/arm/st/h7/stm32h7.dtsi:1251 */
			status = "disabled";                   /* in zephyr/dts/arm/st/h7/stm32h7.dtsi:1253 */
		};

		/* node '/soc/sai1@40015824' defined in zephyr/dts/arm/st/h7/stm32h7.dtsi:1256 */
		sai1_b: sai1@40015824 {
			compatible = "st,stm32-sai";           /* in zephyr/dts/arm/st/h7/stm32h7.dtsi:1257 */
			#address-cells = < 0x1 >;              /* in zephyr/dts/arm/st/h7/stm32h7.dtsi:1258 */
			#size-cells = < 0x0 >;                 /* in zephyr/dts/arm/st/h7/stm32h7.dtsi:1259 */
			reg = < 0x40015824 0x20 >;             /* in zephyr/dts/arm/st/h7/stm32h7.dtsi:1260 */
			clocks = < &rcc 0xf0 0x400000 >,
			         < &rcc 0xb 0x1400050 >;       /* in zephyr/dts/arm/st/h7/stm32h7.dtsi:1261 */
			dmas = < &dma1 0x3 0x58 0x22800 0x0 >; /* in zephyr/dts/arm/st/h7/stm32h7.dtsi:1263 */
			status = "disabled";                   /* in zephyr/dts/arm/st/h7/stm32h7.dtsi:1265 */
		};

		/* node '/soc/comparator@5800380c' defined in zephyr/dts/arm/st/h7/stm32h7.dtsi:1268 */
		comp1_ch1: comparator@5800380c {
			compatible = "st,stm32h7-comp",
			             "st,stm32-comp";   /* in zephyr/dts/arm/st/h7/stm32h7.dtsi:1269 */
			reg = < 0x5800380c 0x200 >;     /* in zephyr/dts/arm/st/h7/stm32h7.dtsi:1270 */
			interrupts = < 0x89 0x0 >;      /* in zephyr/dts/arm/st/h7/stm32h7.dtsi:1271 */
			st,exti-line = < 0x14 >;        /* in zephyr/dts/arm/st/h7/stm32h7.dtsi:1272 */
			clocks = < &rcc 0xf4 0x4000 >;  /* in zephyr/dts/arm/st/h7/stm32h7.dtsi:1273 */
			status = "disabled";            /* in zephyr/dts/arm/st/h7/stm32h7.dtsi:1274 */
		};

		/* node '/soc/comparator@58003810' defined in zephyr/dts/arm/st/h7/stm32h7.dtsi:1277 */
		comp1_ch2: comparator@58003810 {
			compatible = "st,stm32h7-comp",
			             "st,stm32-comp";   /* in zephyr/dts/arm/st/h7/stm32h7.dtsi:1278 */
			reg = < 0x58003810 0x200 >;     /* in zephyr/dts/arm/st/h7/stm32h7.dtsi:1279 */
			interrupts = < 0x89 0x0 >;      /* in zephyr/dts/arm/st/h7/stm32h7.dtsi:1280 */
			st,exti-line = < 0x14 >;        /* in zephyr/dts/arm/st/h7/stm32h7.dtsi:1281 */
			clocks = < &rcc 0xf4 0x4000 >;  /* in zephyr/dts/arm/st/h7/stm32h7.dtsi:1282 */
			status = "disabled";            /* in zephyr/dts/arm/st/h7/stm32h7.dtsi:1283 */
		};

		/* node '/soc/crc@58024c00' defined in zephyr/dts/arm/st/h7/stm32h7.dtsi:1286 */
		crc: crc@58024c00 {
			compatible = "st,stm32-crc";    /* in zephyr/dts/arm/st/h7/stm32h7.dtsi:1287 */
			reg = < 0x58024c00 0x400 >;     /* in zephyr/dts/arm/st/h7/stm32h7.dtsi:1288 */
			clocks = < &rcc 0xe0 0x80000 >; /* in zephyr/dts/arm/st/h7/stm32h7.dtsi:1289 */
			resets = < &rctl 0x1113 >;      /* in zephyr/dts/arm/st/h7/stm32h7.dtsi:1290 */
			status = "disabled";            /* in zephyr/dts/arm/st/h7/stm32h7.dtsi:1291 */
		};

		/* node '/soc/usb@40080000' defined in zephyr/dts/arm/st/h7/stm32h742.dtsi:32 */
		usbotg_fs: usb@40080000 {
			compatible = "st,stm32-otgfs";    /* in zephyr/dts/arm/st/h7/stm32h742.dtsi:33 */
			reg = < 0x40080000 0x40000 >;     /* in zephyr/dts/arm/st/h7/stm32h742.dtsi:34 */
			interrupts = < 0x65 0x0 >,
			             < 0x62 0x0 >,
			             < 0x63 0x0 >;        /* in zephyr/dts/arm/st/h7/stm32h742.dtsi:35 */
			interrupt-names = "otgfs",
			                  "ep1_out",
			                  "ep1_in";       /* in zephyr/dts/arm/st/h7/stm32h742.dtsi:36 */
			num-bidir-endpoints = < 0x9 >;    /* in zephyr/dts/arm/st/h7/stm32h742.dtsi:37 */
			ram-size = < 0x1000 >;            /* in zephyr/dts/arm/st/h7/stm32h742.dtsi:38 */
			maximum-speed = "full-speed";     /* in zephyr/dts/arm/st/h7/stm32h742.dtsi:39 */
			clocks = < &rcc 0xd8 0x8000000 >,
			         < &rcc 0x5 0x3340054 >;  /* in zephyr/dts/arm/st/h7/stm32h742.dtsi:40 */
			phys = < &otghs_fs_phy >;         /* in zephyr/dts/arm/st/h7/stm32h742.dtsi:42 */
			status = "disabled";              /* in zephyr/dts/arm/st/h7/stm32h742.dtsi:43 */
		};

		/* node '/soc/display-controller@50001000' defined in zephyr/dts/arm/st/h7/stm32h742.dtsi:46 */
		ltdc: display-controller@50001000 {
			compatible = "st,stm32-ltdc"; /* in zephyr/dts/arm/st/h7/stm32h742.dtsi:47 */
			reg = < 0x50001000 0x200 >;   /* in zephyr/dts/arm/st/h7/stm32h742.dtsi:48 */
			interrupts = < 0x58 0x0 >,
			             < 0x59 0x0 >;    /* in zephyr/dts/arm/st/h7/stm32h742.dtsi:49 */
			interrupt-names = "ltdc",
			                  "ltdc_er";  /* in zephyr/dts/arm/st/h7/stm32h742.dtsi:50 */
			clocks = < &rcc 0xe4 0x8 >;   /* in zephyr/dts/arm/st/h7/stm32h742.dtsi:51 */
			resets = < &rctl 0x1183 >;    /* in zephyr/dts/arm/st/h7/stm32h742.dtsi:52 */
			status = "disabled";          /* in zephyr/dts/arm/st/h7/stm32h742.dtsi:53 */
		};
	};

	/* node '/cpus' defined in zephyr/dts/arm/st/h7/stm32h7.dtsi:34 */
	cpus {
		#address-cells = < 0x1 >; /* in zephyr/dts/arm/st/h7/stm32h7.dtsi:35 */
		#size-cells = < 0x0 >;    /* in zephyr/dts/arm/st/h7/stm32h7.dtsi:36 */

		/* node '/cpus/cpu@0' defined in zephyr/dts/arm/st/h7/stm32h7.dtsi:38 */
		cpu0: cpu@0 {
			device_type = "cpu";          /* in zephyr/dts/arm/st/h7/stm32h7.dtsi:39 */
			compatible = "arm,cortex-m7"; /* in zephyr/dts/arm/st/h7/stm32h7.dtsi:40 */
			reg = < 0x0 >;                /* in zephyr/dts/arm/st/h7/stm32h7.dtsi:41 */
			#address-cells = < 0x1 >;     /* in zephyr/dts/arm/st/h7/stm32h7.dtsi:42 */
			#size-cells = < 0x1 >;        /* in zephyr/dts/arm/st/h7/stm32h7.dtsi:43 */

			/* node '/cpus/cpu@0/mpu@e000ed90' defined in zephyr/dts/arm/st/h7/stm32h7.dtsi:45 */
			mpu: mpu@e000ed90 {
				compatible = "arm,armv7m-mpu"; /* in zephyr/dts/arm/st/h7/stm32h7.dtsi:46 */
				reg = < 0xe000ed90 0x40 >;     /* in zephyr/dts/arm/st/h7/stm32h7.dtsi:47 */
			};
		};
	};

	/* node '/memory@0' defined in zephyr/dts/arm/st/h7/stm32h7.dtsi:52 */
	itcm: memory@0 {
		compatible = "zephyr,memory-region",
		             "arm,itcm";             /* in zephyr/dts/arm/st/h7/stm32h7.dtsi:53 */
		reg = < 0x0 0x10000 >;               /* in zephyr/dts/arm/st/h7/stm32h7.dtsi:54 */
		zephyr,memory-region = "ITCM";       /* in zephyr/dts/arm/st/h7/stm32h7.dtsi:55 */
	};

	/* node '/memory@20000000' defined in zephyr/dts/arm/st/h7/stm32h7.dtsi:58 */
	dtcm: memory@20000000 {
		compatible = "zephyr,memory-region",
		             "arm,dtcm";             /* in zephyr/dts/arm/st/h7/stm32h7.dtsi:59 */
		reg = < 0x20000000 0x20000 >;        /* in zephyr/dts/arm/st/h7/stm32h7.dtsi:60 */
		zephyr,memory-region = "DTCM";       /* in zephyr/dts/arm/st/h7/stm32h7.dtsi:61 */
	};

	/* node '/memory@90000000' defined in zephyr/dts/arm/st/h7/stm32h7.dtsi:64 */
	ext_memory: memory@90000000 {
		compatible = "zephyr,memory-region"; /* in zephyr/dts/arm/st/h7/stm32h7.dtsi:65 */
		reg = < 0x90000000 0x10000000 >;     /* in zephyr/dts/arm/st/h7/stm32h7.dtsi:66 */
		zephyr,memory-region = "EXTMEM";     /* in zephyr/dts/arm/st/h7/stm32h7.dtsi:67 */
		zephyr,memory-attr = < 0x2000000 >;  /* in zephyr/dts/arm/st/h7/stm32h7.dtsi:68 */
	};

	/* node '/clocks' defined in zephyr/dts/arm/st/h7/stm32h7.dtsi:71 */
	clocks {
		#address-cells = < 0x1 >; /* in zephyr/dts/arm/st/h7/stm32h7.dtsi:72 */
		#size-cells = < 0x0 >;    /* in zephyr/dts/arm/st/h7/stm32h7.dtsi:73 */

		/* node '/clocks/clk-hse' defined in zephyr/dts/arm/st/h7/stm32h7.dtsi:75 */
		clk_hse: clk-hse {
			#clock-cells = < 0x0 >;            /* in zephyr/dts/arm/st/h7/stm32h7.dtsi:76 */
			compatible = "st,stm32-hse-clock"; /* in zephyr/dts/arm/st/h7/stm32h7.dtsi:77 */
			hse-bypass;                        /* in ../Projects/stm32_system_on_module/fw/som/boards/hagzey/som/som.dts:61 */
			clock-frequency = < 0x7a1200 >;    /* in ../Projects/stm32_system_on_module/fw/som/boards/hagzey/som/som.dts:62 */
			status = "okay";                   /* in ../Projects/stm32_system_on_module/fw/som/boards/hagzey/som/som.dts:63 */
			phandle = < 0x11 >;                /* in ../Projects/stm32_system_on_module/fw/som/boards/hagzey/som/som.dts:72 */
		};

		/* node '/clocks/clk-hsi' defined in zephyr/dts/arm/st/h7/stm32h7.dtsi:82 */
		clk_hsi: clk-hsi {
			#clock-cells = < 0x0 >;              /* in zephyr/dts/arm/st/h7/stm32h7.dtsi:83 */
			compatible = "st,stm32h7-hsi-clock"; /* in zephyr/dts/arm/st/h7/stm32h7.dtsi:84 */
			hsi-div = < 0x1 >;                   /* in zephyr/dts/arm/st/h7/stm32h7.dtsi:85 */
			clock-frequency = < 0x3d09000 >;     /* in zephyr/dts/arm/st/h7/stm32h7.dtsi:86 */
			status = "disabled";                 /* in zephyr/dts/arm/st/h7/stm32h7.dtsi:87 */
		};

		/* node '/clocks/clk-hsi48' defined in zephyr/dts/arm/st/h7/stm32h7.dtsi:90 */
		clk_hsi48: clk-hsi48 {
			#clock-cells = < 0x0 >;          /* in zephyr/dts/arm/st/h7/stm32h7.dtsi:91 */
			compatible = "fixed-clock";      /* in zephyr/dts/arm/st/h7/stm32h7.dtsi:92 */
			clock-frequency = < 0x2dc6c00 >; /* in zephyr/dts/arm/st/h7/stm32h7.dtsi:93 */
			status = "disabled";             /* in zephyr/dts/arm/st/h7/stm32h7.dtsi:94 */
		};

		/* node '/clocks/clk-csi' defined in zephyr/dts/arm/st/h7/stm32h7.dtsi:97 */
		clk_csi: clk-csi {
			#clock-cells = < 0x0 >;         /* in zephyr/dts/arm/st/h7/stm32h7.dtsi:98 */
			compatible = "fixed-clock";     /* in zephyr/dts/arm/st/h7/stm32h7.dtsi:99 */
			clock-frequency = < 0x3d0900 >; /* in zephyr/dts/arm/st/h7/stm32h7.dtsi:100 */
			status = "disabled";            /* in zephyr/dts/arm/st/h7/stm32h7.dtsi:101 */
		};

		/* node '/clocks/clk-lse' defined in zephyr/dts/arm/st/h7/stm32h7.dtsi:104 */
		clk_lse: clk-lse {
			#clock-cells = < 0x0 >;            /* in zephyr/dts/arm/st/h7/stm32h7.dtsi:105 */
			compatible = "st,stm32-lse-clock"; /* in zephyr/dts/arm/st/h7/stm32h7.dtsi:106 */
			clock-frequency = < 0x8000 >;      /* in zephyr/dts/arm/st/h7/stm32h7.dtsi:107 */
			driving-capability = < 0x0 >;      /* in zephyr/dts/arm/st/h7/stm32h7.dtsi:108 */
			status = "disabled";               /* in zephyr/dts/arm/st/h7/stm32h7.dtsi:109 */
		};

		/* node '/clocks/clk-lsi' defined in zephyr/dts/arm/st/h7/stm32h7.dtsi:112 */
		clk_lsi: clk-lsi {
			#clock-cells = < 0x0 >;       /* in zephyr/dts/arm/st/h7/stm32h7.dtsi:113 */
			compatible = "fixed-clock";   /* in zephyr/dts/arm/st/h7/stm32h7.dtsi:114 */
			clock-frequency = < 0x7d00 >; /* in zephyr/dts/arm/st/h7/stm32h7.dtsi:115 */
			status = "disabled";          /* in zephyr/dts/arm/st/h7/stm32h7.dtsi:116 */
		};

		/* node '/clocks/pll@0' defined in zephyr/dts/arm/st/h7/stm32h7.dtsi:119 */
		pll: pll@0 {
			#clock-cells = < 0x0 >;              /* in zephyr/dts/arm/st/h7/stm32h7.dtsi:120 */
			compatible = "st,stm32h7-pll-clock"; /* in zephyr/dts/arm/st/h7/stm32h7.dtsi:121 */
			reg = < 0x0 >;                       /* in zephyr/dts/arm/st/h7/stm32h7.dtsi:122 */
			div-m = < 0x2 >;                     /* in ../Projects/stm32_system_on_module/fw/som/boards/hagzey/som/som.dts:67 */
			mul-n = < 0xf0 >;                    /* in ../Projects/stm32_system_on_module/fw/som/boards/hagzey/som/som.dts:68 */
			div-p = < 0x2 >;                     /* in ../Projects/stm32_system_on_module/fw/som/boards/hagzey/som/som.dts:69 */
			div-q = < 0x2 >;                     /* in ../Projects/stm32_system_on_module/fw/som/boards/hagzey/som/som.dts:70 */
			div-r = < 0x2 >;                     /* in ../Projects/stm32_system_on_module/fw/som/boards/hagzey/som/som.dts:71 */
			clocks = < &clk_hse >;               /* in ../Projects/stm32_system_on_module/fw/som/boards/hagzey/som/som.dts:72 */
			status = "okay";                     /* in ../Projects/stm32_system_on_module/fw/som/boards/hagzey/som/som.dts:73 */
			phandle = < 0x2 >;                   /* in ../Projects/stm32_system_on_module/fw/som/boards/hagzey/som/som.dts:77 */
		};

		/* node '/clocks/pll@1' defined in zephyr/dts/arm/st/h7/stm32h7.dtsi:126 */
		pll2: pll@1 {
			#clock-cells = < 0x0 >;              /* in zephyr/dts/arm/st/h7/stm32h7.dtsi:127 */
			compatible = "st,stm32h7-pll-clock"; /* in zephyr/dts/arm/st/h7/stm32h7.dtsi:128 */
			reg = < 0x1 >;                       /* in zephyr/dts/arm/st/h7/stm32h7.dtsi:129 */
			status = "disabled";                 /* in zephyr/dts/arm/st/h7/stm32h7.dtsi:130 */
		};

		/* node '/clocks/pll@2' defined in zephyr/dts/arm/st/h7/stm32h7.dtsi:133 */
		pll3: pll@2 {
			#clock-cells = < 0x0 >;              /* in zephyr/dts/arm/st/h7/stm32h7.dtsi:134 */
			compatible = "st,stm32h7-pll-clock"; /* in zephyr/dts/arm/st/h7/stm32h7.dtsi:135 */
			reg = < 0x2 >;                       /* in zephyr/dts/arm/st/h7/stm32h7.dtsi:136 */
			status = "disabled";                 /* in zephyr/dts/arm/st/h7/stm32h7.dtsi:137 */
		};

		/* node '/clocks/perck' defined in zephyr/dts/arm/st/h7/stm32h7.dtsi:140 */
		perck: perck {
			#clock-cells = < 0x0 >;            /* in zephyr/dts/arm/st/h7/stm32h7.dtsi:141 */
			compatible = "st,stm32-clock-mux"; /* in zephyr/dts/arm/st/h7/stm32h7.dtsi:142 */
			status = "disabled";               /* in zephyr/dts/arm/st/h7/stm32h7.dtsi:143 */
		};
	};

	/* node '/mcos' defined in zephyr/dts/arm/st/h7/stm32h7.dtsi:147 */
	mcos {

		/* node '/mcos/mco1' defined in zephyr/dts/arm/st/h7/stm32h7.dtsi:148 */
		mco1: mco1 {
			compatible = "st,stm32-clock-mco"; /* in zephyr/dts/arm/st/h7/stm32h7.dtsi:149 */
			clock-names = "clksel";            /* in zephyr/dts/arm/st/h7/stm32h7.dtsi:150 */
			status = "disabled";               /* in zephyr/dts/arm/st/h7/stm32h7.dtsi:151 */
		};

		/* node '/mcos/mco2' defined in zephyr/dts/arm/st/h7/stm32h7.dtsi:154 */
		mco2: mco2 {
			compatible = "st,stm32-clock-mco"; /* in zephyr/dts/arm/st/h7/stm32h7.dtsi:155 */
			clock-names = "clksel";            /* in zephyr/dts/arm/st/h7/stm32h7.dtsi:156 */
			status = "disabled";               /* in zephyr/dts/arm/st/h7/stm32h7.dtsi:157 */
		};
	};

	/* node '/dietemp' defined in zephyr/dts/arm/st/h7/stm32h7.dtsi:1295 */
	die_temp: dietemp {
		compatible = "st,stm32-temp-cal"; /* in zephyr/dts/arm/st/h7/stm32h7.dtsi:1296 */
		nvmem-cells = < &ts_cal1_otp >,
		              < &ts_cal2_otp >;   /* in zephyr/dts/arm/st/h7/stm32h7.dtsi:1297 */
		nvmem-cell-names = "TS_CAL1",
		                   "TS_CAL2";     /* in zephyr/dts/arm/st/h7/stm32h7.dtsi:1298 */
		ts-cal1-temp = < 0x1e >;          /* in zephyr/dts/arm/st/h7/stm32h7.dtsi:1299 */
		ts-cal2-temp = < 0x6e >;          /* in zephyr/dts/arm/st/h7/stm32h7.dtsi:1300 */
		ts-cal-vrefanalog = < 0xce4 >;    /* in zephyr/dts/arm/st/h7/stm32h7.dtsi:1301 */
		ts-cal-resolution = < 0x10 >;     /* in zephyr/dts/arm/st/h7/stm32h7.dtsi:1302 */
		io-channels = < &adc3 0x12 >;     /* in zephyr/dts/arm/st/h7/stm32h7.dtsi:1303 */
		status = "disabled";              /* in zephyr/dts/arm/st/h7/stm32h7.dtsi:1304 */
	};

	/* node '/vbat' defined in zephyr/dts/arm/st/h7/stm32h7.dtsi:1307 */
	vbat: vbat {
		compatible = "st,stm32-vbat"; /* in zephyr/dts/arm/st/h7/stm32h7.dtsi:1308 */
		ratio = < 0x4 >;              /* in zephyr/dts/arm/st/h7/stm32h7.dtsi:1309 */
		status = "disabled";          /* in zephyr/dts/arm/st/h7/stm32h7.dtsi:1310 */
		io-channels = < &adc3 0x11 >; /* in zephyr/dts/arm/st/h7/stm32h742.dtsi:104 */
	};

	/* node '/vref' defined in zephyr/dts/arm/st/h7/stm32h7.dtsi:1313 */
	vref: vref {
		compatible = "st,stm32-vref";      /* in zephyr/dts/arm/st/h7/stm32h7.dtsi:1314 */
		nvmem-cells = < &vrefint_otp >;    /* in zephyr/dts/arm/st/h7/stm32h7.dtsi:1315 */
		vrefint-cal-mv = < 0xce4 >;        /* in zephyr/dts/arm/st/h7/stm32h7.dtsi:1316 */
		vrefint-cal-resolution = < 0x10 >; /* in zephyr/dts/arm/st/h7/stm32h7.dtsi:1317 */
		status = "disabled";               /* in zephyr/dts/arm/st/h7/stm32h7.dtsi:1318 */
		io-channels = < &adc3 0x13 >;      /* in zephyr/dts/arm/st/h7/stm32h742.dtsi:100 */
	};

	/* node '/smbus1' defined in zephyr/dts/arm/st/h7/stm32h7.dtsi:1321 */
	smbus1: smbus1 {
		compatible = "st,stm32-smbus"; /* in zephyr/dts/arm/st/h7/stm32h7.dtsi:1322 */
		#address-cells = < 0x1 >;      /* in zephyr/dts/arm/st/h7/stm32h7.dtsi:1323 */
		#size-cells = < 0x0 >;         /* in zephyr/dts/arm/st/h7/stm32h7.dtsi:1324 */
		i2c = < &i2c1 >;               /* in zephyr/dts/arm/st/h7/stm32h7.dtsi:1325 */
		status = "disabled";           /* in zephyr/dts/arm/st/h7/stm32h7.dtsi:1326 */
	};

	/* node '/smbus2' defined in zephyr/dts/arm/st/h7/stm32h7.dtsi:1329 */
	smbus2: smbus2 {
		compatible = "st,stm32-smbus"; /* in zephyr/dts/arm/st/h7/stm32h7.dtsi:1330 */
		#address-cells = < 0x1 >;      /* in zephyr/dts/arm/st/h7/stm32h7.dtsi:1331 */
		#size-cells = < 0x0 >;         /* in zephyr/dts/arm/st/h7/stm32h7.dtsi:1332 */
		i2c = < &i2c2 >;               /* in zephyr/dts/arm/st/h7/stm32h7.dtsi:1333 */
		status = "disabled";           /* in zephyr/dts/arm/st/h7/stm32h7.dtsi:1334 */
	};

	/* node '/smbus3' defined in zephyr/dts/arm/st/h7/stm32h7.dtsi:1337 */
	smbus3: smbus3 {
		compatible = "st,stm32-smbus"; /* in zephyr/dts/arm/st/h7/stm32h7.dtsi:1338 */
		#address-cells = < 0x1 >;      /* in zephyr/dts/arm/st/h7/stm32h7.dtsi:1339 */
		#size-cells = < 0x0 >;         /* in zephyr/dts/arm/st/h7/stm32h7.dtsi:1340 */
		i2c = < &i2c3 >;               /* in zephyr/dts/arm/st/h7/stm32h7.dtsi:1341 */
		status = "disabled";           /* in zephyr/dts/arm/st/h7/stm32h7.dtsi:1342 */
	};

	/* node '/smbus4' defined in zephyr/dts/arm/st/h7/stm32h7.dtsi:1345 */
	smbus4: smbus4 {
		compatible = "st,stm32-smbus"; /* in zephyr/dts/arm/st/h7/stm32h7.dtsi:1346 */
		#address-cells = < 0x1 >;      /* in zephyr/dts/arm/st/h7/stm32h7.dtsi:1347 */
		#size-cells = < 0x0 >;         /* in zephyr/dts/arm/st/h7/stm32h7.dtsi:1348 */
		i2c = < &i2c4 >;               /* in zephyr/dts/arm/st/h7/stm32h7.dtsi:1349 */
		status = "disabled";           /* in zephyr/dts/arm/st/h7/stm32h7.dtsi:1350 */
	};

	/* node '/memory@24000000' defined in zephyr/dts/arm/st/h7/stm32h742.dtsi:66 */
	sram0: memory@24000000 {
		compatible = "zephyr,memory-region",
		             "mmio-sram";            /* in zephyr/dts/arm/st/h7/stm32h742.dtsi:67 */
		zephyr,memory-region = "SRAM0";      /* in zephyr/dts/arm/st/h7/stm32h742.dtsi:69 */
		reg = < 0x24000000 0x80000 >;        /* in zephyr/dts/arm/st/h7/stm32h743.dtsi:17 */
	};

	/* node '/memory@30000000' defined in zephyr/dts/arm/st/h7/stm32h742.dtsi:73 */
	sram1: memory@30000000 {
		compatible = "zephyr,memory-region",
		             "mmio-sram";            /* in zephyr/dts/arm/st/h7/stm32h742.dtsi:74 */
		zephyr,memory-region = "SRAM1";      /* in zephyr/dts/arm/st/h7/stm32h742.dtsi:76 */
		reg = < 0x30000000 0x20000 >;        /* in zephyr/dts/arm/st/h7/stm32h743.dtsi:22 */
	};

	/* node '/memory@30020000' defined in zephyr/dts/arm/st/h7/stm32h742.dtsi:80 */
	sram2: memory@30020000 {
		compatible = "zephyr,memory-region",
		             "mmio-sram";            /* in zephyr/dts/arm/st/h7/stm32h742.dtsi:81 */
		zephyr,memory-region = "SRAM2";      /* in zephyr/dts/arm/st/h7/stm32h742.dtsi:83 */
		reg = < 0x30020000 0x20000 >;        /* in zephyr/dts/arm/st/h7/stm32h743.dtsi:27 */
		#memory-region-cells = < 0x0 >;      /* in zephyr/dts/arm/st/h7/stm32h743.dtsi:28 */
	};

	/* node '/memory@38000000' defined in zephyr/dts/arm/st/h7/stm32h742.dtsi:88 */
	sram4: memory@38000000 {
		compatible = "zephyr,memory-region",
		             "mmio-sram";            /* in zephyr/dts/arm/st/h7/stm32h742.dtsi:89 */
		reg = < 0x38000000 0x10000 >;        /* in zephyr/dts/arm/st/h7/stm32h742.dtsi:90 */
		zephyr,memory-region = "SRAM4";      /* in zephyr/dts/arm/st/h7/stm32h742.dtsi:91 */
	};

	/* node '/otghs_fs_phy' defined in zephyr/dts/arm/st/h7/stm32h742.dtsi:94 */
	otghs_fs_phy: otghs_fs_phy {
		compatible = "usb-nop-xceiv"; /* in zephyr/dts/arm/st/h7/stm32h742.dtsi:95 */
		#phy-cells = < 0x0 >;         /* in zephyr/dts/arm/st/h7/stm32h742.dtsi:96 */
		phandle = < 0x10 >;           /* in zephyr/dts/arm/st/h7/stm32h742.dtsi:42 */
	};

	/* node '/memory@30040000' defined in zephyr/dts/arm/st/h7/stm32h743.dtsi:32 */
	sram3: memory@30040000 {
		compatible = "zephyr,memory-region",
		             "mmio-sram";            /* in zephyr/dts/arm/st/h7/stm32h743.dtsi:33 */
		reg = < 0x30040000 0x8000 >;         /* in zephyr/dts/arm/st/h7/stm32h743.dtsi:34 */
		zephyr,memory-region = "SRAM3";      /* in zephyr/dts/arm/st/h7/stm32h743.dtsi:35 */
		#memory-region-cells = < 0x0 >;      /* in zephyr/dts/arm/st/h7/stm32h743.dtsi:36 */
		phandle = < 0x8 >;                   /* in zephyr/dts/arm/st/h7/stm32h743.dtsi:41 */
	};
};
